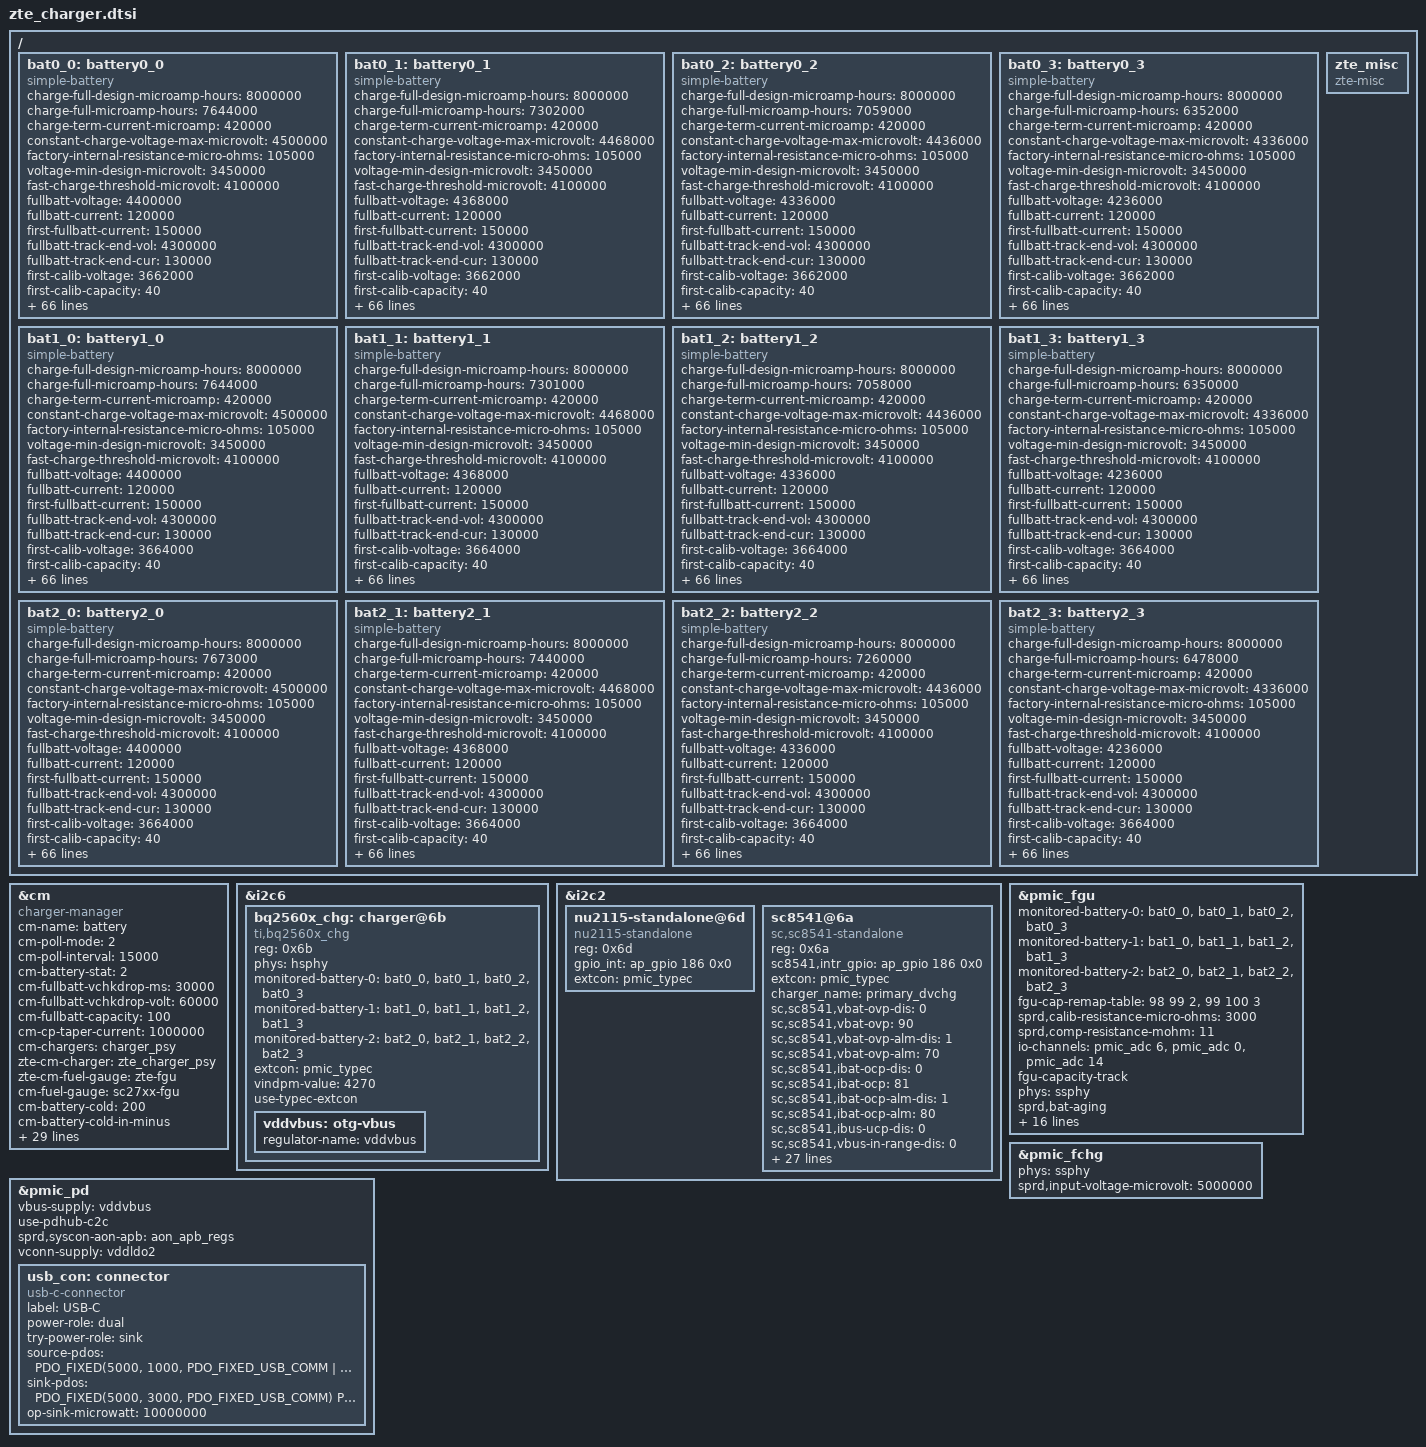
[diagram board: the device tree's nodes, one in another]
#include <dt-bindings/usb/pd.h>


/ {
	bat0_0: battery0_0 {
		compatible = "simple-battery";
		status = "okay";
		charge-full-design-microamp-hours = <5000000>;
		/*Minimum Capacity 4870*0.9 = 4383 4870*0.94 = 4558 4870*0.95 = 4626 4870*0.96 = 4675,4870*0.98 = 4772  we use *0.98 */
		charge-full-microamp-hours = <4772000>;
		charge-term-current-microamp = <420000>;
		constant-charge-voltage-max-microvolt = <4400000>;
		factory-internal-resistance-micro-ohms = <225000>;
		voltage-min-design-microvolt = <3450000>;

		fast-charge-threshold-microvolt = <4100000>;
		fullbatt-voltage = <4300000>;
		fullbatt-current = <120000>;
		first-fullbatt-current = <150000>;
		fullbatt-track-end-vol = <4295000>;
		fullbatt-track-end-cur = <130000>;
		first-calib-voltage = <3580000>;
		first-calib-capacity = <50>;

		ir-cv-offset-microvolt = <100000>;
		ir-rc-micro-ohms = <20000>;
		ir-us-upper-limit-microvolt = <4500000>;

		batt-id-list = <300 10 390 20>;  /* kohm, scud / ningde / tianmao /guanyu*/
		ocv-capacity-celsius = <20>;
		ocv-capacity-table-0 = <4374000 100>, <4308000 95>, <4250000 90>,
					<4193000 85>, <4139000 80>, <4086000 75>,
					<4037000 70>, <3992000 65>, <3951000 60>,
					<3896000 55>, <3860000 50>, <3836000 45>,
					<3814000 40>, <3797000 35>, <3784000 30>,
					<3767000 25>, <3749000 20>, <3726000 15>,
					<3697000 10>, <3683000 5>, <3400000 0>;
		/* NTC 100k, Vref 1850mV, R pull-up 110K, R pull-down 1000k */
		voltage-temp-table = <1568441 750>, <1534549 800>, <1515014 850>,
					<1475819 900>, <1402274 950>, <1334550 1000>,
					<1222195 1050>, <1131821 1100>, <1035662 1150>,
					<936426 1200>, <837104 1250>, <740441 1300>,
					<648801 1350>, <563916 1400>, <486937 1450>,
					<418193 1500>, <357806 1550>, <305304 1600>,
					<260067 1650>, <221438 1700>, <188468 1750>;
		capacity-temp-table = <25 100>, <10 100>, <0 97>, <(-10) 89>, <(-20) 57>;
		resistance-temp-table = <25 100>, <10 332>, <0 507>, <(-10) 569>, <(-20) 675>;
		charge-sdp-current-microamp = <700000 500000>;
		charge-dcp-current-microamp = <2000000 3000000>;
		charge-cdp-current-microamp = <1500000 1500000>;
		charge-unknown-current-microamp = <1000000 1000000>;
		charge-fchg-current-microamp = <3400000 2000000>;
		charge-flash-current-microamp = <3400000 2700000>;

		cap-calib-energy-density-ocv-table = <3350000 3800000>, <4150000 4350000>;
		cap-track-energy-density-ocv-table = <3400000 3722000>;

		dcp-jeita-temp-table = <1000 1030 0 4400000>,
					<1050 1080 1400000 4400000>,
					<1100 1180 1400000 4400000>,
					<1450 1420 3400000 4400000>,
					<1550 1520 2400000 4100000>;
		sdp-jeita-temp-table = <1000 1030 0 4400000>,
					<1050 1080 1400000 4400000>,
					<1100 1180 1400000 4400000>,
					<1450 1420 3400000 4400000>,
					<1550 1520 2400000 4100000>;
		cdp-jeita-temp-table = <1000 1030 0 4400000>,
					<1050 1080 1400000 4400000>,
					<1100 1180 1400000 4400000>,
					<1450 1420 3400000 4400000>,
					<1550 1520 2400000 4100000>;
		unknown-jeita-temp-table = <1000 1030 0 4400000>,
					<1050 1080 1400000 4400000>,
					<1100 1180 1400000 4400000>,
					<1450 1420 3400000 4400000>,
					<1550 1520 2400000 4100000>;
		fchg-jeita-temp-table = <1000 1030 0 4400000>,
					<1050 1080 1400000 4400000>,
					<1100 1180 1400000 4400000>,
					<1450 1420 3400000 4400000>,
					<1550 1520 2400000 4100000>;
		flash-jeita-temp-table = <1000 1030 0 4400000>,
					<1050 1080 1400000 4400000>,
					<1100 1180 1400000 4400000>,
					<1450 1420 3400000 4400000>,
					<1550 1520 2400000 4100000>;
	};

	bat0_1: battery0_1 {
		compatible = "simple-battery";
		status = "okay";
		charge-full-design-microamp-hours = <5000000>;
		/*Minimum Capacity 4870*0.9 = 4383 4870*0.94 = 4558 4870*0.95 = 4626 4870*0.96 = 4675,4870*0.98 = 4772  we use *0.98 */
		charge-full-microamp-hours = <4772000>;
		charge-term-current-microamp = <420000>;
		constant-charge-voltage-max-microvolt = <4400000>;
		factory-internal-resistance-micro-ohms = <225000>;
		voltage-min-design-microvolt = <3450000>;

		fast-charge-threshold-microvolt = <4100000>;
		fullbatt-voltage = <4300000>;
		fullbatt-current = <120000>;
		first-fullbatt-current = <150000>;
		fullbatt-track-end-vol = <4295000>;
		fullbatt-track-end-cur = <130000>;
		first-calib-voltage = <3580000>;
		first-calib-capacity = <50>;

		ir-cv-offset-microvolt = <100000>;
		ir-rc-micro-ohms = <20000>;
		ir-us-upper-limit-microvolt = <4500000>;

		batt-id-list = <300 10 390 20>;  /* kohm, scud / ningde / tianmao /guanyu*/
		ocv-capacity-celsius = <20>;
		ocv-capacity-table-0 = <4374000 100>, <4308000 95>, <4250000 90>,
					<4193000 85>, <4139000 80>, <4086000 75>,
					<4037000 70>, <3992000 65>, <3951000 60>,
					<3896000 55>, <3860000 50>, <3836000 45>,
					<3814000 40>, <3797000 35>, <3784000 30>,
					<3767000 25>, <3749000 20>, <3726000 15>,
					<3697000 10>, <3683000 5>, <3400000 0>;
		/* NTC 100k, Vref 1850mV, R pull-up 110K, R pull-down 1000k */
		voltage-temp-table = <1568441 750>, <1534549 800>, <1515014 850>,
					<1475819 900>, <1402274 950>, <1334550 1000>,
					<1222195 1050>, <1131821 1100>, <1035662 1150>,
					<936426 1200>, <837104 1250>, <740441 1300>,
					<648801 1350>, <563916 1400>, <486937 1450>,
					<418193 1500>, <357806 1550>, <305304 1600>,
					<260067 1650>, <221438 1700>, <188468 1750>;
		capacity-temp-table = <25 100>, <10 100>, <0 97>, <(-10) 89>, <(-20) 57>;
		resistance-temp-table = <25 100>, <10 332>, <0 507>, <(-10) 569>, <(-20) 675>;
		charge-sdp-current-microamp = <700000 500000>;
		charge-dcp-current-microamp = <2000000 3000000>;
		charge-cdp-current-microamp = <1500000 1500000>;
		charge-unknown-current-microamp = <1000000 1000000>;
		charge-fchg-current-microamp = <3400000 2000000>;
		charge-flash-current-microamp = <3400000 2700000>;

		cap-calib-energy-density-ocv-table = <3350000 3800000>, <4150000 4350000>;
		cap-track-energy-density-ocv-table = <3400000 3722000>;

		dcp-jeita-temp-table = <1000 1030 0 4400000>,
					<1050 1080 1400000 4400000>,
					<1100 1180 1400000 4400000>,
					<1450 1420 3400000 4400000>,
					<1550 1520 2400000 4100000>;
		sdp-jeita-temp-table = <1000 1030 0 4400000>,
					<1050 1080 1400000 4400000>,
					<1100 1180 1400000 4400000>,
					<1450 1420 3400000 4400000>,
					<1550 1520 2400000 4100000>;
		cdp-jeita-temp-table = <1000 1030 0 4400000>,
					<1050 1080 1400000 4400000>,
					<1100 1180 1400000 4400000>,
					<1450 1420 3400000 4400000>,
					<1550 1520 2400000 4100000>;
		unknown-jeita-temp-table = <1000 1030 0 4400000>,
					<1050 1080 1400000 4400000>,
					<1100 1180 1400000 4400000>,
					<1450 1420 3400000 4400000>,
					<1550 1520 2400000 4100000>;
		fchg-jeita-temp-table = <1000 1030 0 4400000>,
					<1050 1080 1400000 4400000>,
					<1100 1180 1400000 4400000>,
					<1450 1420 3400000 4400000>,
					<1550 1520 2400000 4100000>;
		flash-jeita-temp-table = <1000 1030 0 4400000>,
					<1050 1080 1400000 4400000>,
					<1100 1180 1400000 4400000>,
					<1450 1420 3400000 4400000>,
					<1550 1520 2400000 4100000>;
	};

	bat0_2: battery0_2 {
		compatible = "simple-battery";
		status = "okay";
		charge-full-design-microamp-hours = <5000000>;
		/*Minimum Capacity 4870*0.9 = 4383 4870*0.94 = 4558 4870*0.95 = 4626 4870*0.96 = 4675,4870*0.98 = 4772  we use *0.98 */
		charge-full-microamp-hours = <4772000>;
		charge-term-current-microamp = <420000>;
		constant-charge-voltage-max-microvolt = <4400000>;
		factory-internal-resistance-micro-ohms = <225000>;
		voltage-min-design-microvolt = <3450000>;

		fast-charge-threshold-microvolt = <4100000>;
		fullbatt-voltage = <4300000>;
		fullbatt-current = <120000>;
		first-fullbatt-current = <150000>;
		fullbatt-track-end-vol = <4295000>;
		fullbatt-track-end-cur = <130000>;
		first-calib-voltage = <3580000>;
		first-calib-capacity = <50>;

		ir-cv-offset-microvolt = <100000>;
		ir-rc-micro-ohms = <20000>;
		ir-us-upper-limit-microvolt = <4500000>;

		batt-id-list = <300 10 390 20>;  /* kohm, scud / ningde / tianmao /guanyu*/
		ocv-capacity-celsius = <20>;
		ocv-capacity-table-0 = <4374000 100>, <4308000 95>, <4250000 90>,
					<4193000 85>, <4139000 80>, <4086000 75>,
					<4037000 70>, <3992000 65>, <3951000 60>,
					<3896000 55>, <3860000 50>, <3836000 45>,
					<3814000 40>, <3797000 35>, <3784000 30>,
					<3767000 25>, <3749000 20>, <3726000 15>,
					<3697000 10>, <3683000 5>, <3400000 0>;
		/* NTC 100k, Vref 1850mV, R pull-up 110K, R pull-down 1000k */
		voltage-temp-table = <1568441 750>, <1534549 800>, <1515014 850>,
					<1475819 900>, <1402274 950>, <1334550 1000>,
					<1222195 1050>, <1131821 1100>, <1035662 1150>,
					<936426 1200>, <837104 1250>, <740441 1300>,
					<648801 1350>, <563916 1400>, <486937 1450>,
					<418193 1500>, <357806 1550>, <305304 1600>,
					<260067 1650>, <221438 1700>, <188468 1750>;
		capacity-temp-table = <25 100>, <10 100>, <0 97>, <(-10) 89>, <(-20) 57>;
		resistance-temp-table = <25 100>, <10 332>, <0 507>, <(-10) 569>, <(-20) 675>;
		charge-sdp-current-microamp = <700000 500000>;
		charge-dcp-current-microamp = <2000000 3000000>;
		charge-cdp-current-microamp = <1500000 1500000>;
		charge-unknown-current-microamp = <1000000 1000000>;
		charge-fchg-current-microamp = <3400000 2000000>;
		charge-flash-current-microamp = <3400000 2700000>;

		cap-calib-energy-density-ocv-table = <3350000 3800000>, <4150000 4350000>;
		cap-track-energy-density-ocv-table = <3400000 3722000>;

		dcp-jeita-temp-table = <1000 1030 0 4400000>,
					<1050 1080 1400000 4400000>,
					<1100 1180 1400000 4400000>,
					<1450 1420 3400000 4400000>,
					<1550 1520 2400000 4100000>;
		sdp-jeita-temp-table = <1000 1030 0 4400000>,
					<1050 1080 1400000 4400000>,
					<1100 1180 1400000 4400000>,
					<1450 1420 3400000 4400000>,
					<1550 1520 2400000 4100000>;
		cdp-jeita-temp-table = <1000 1030 0 4400000>,
					<1050 1080 1400000 4400000>,
					<1100 1180 1400000 4400000>,
					<1450 1420 3400000 4400000>,
					<1550 1520 2400000 4100000>;
		unknown-jeita-temp-table = <1000 1030 0 4400000>,
					<1050 1080 1400000 4400000>,
					<1100 1180 1400000 4400000>,
					<1450 1420 3400000 4400000>,
					<1550 1520 2400000 4100000>;
		fchg-jeita-temp-table = <1000 1030 0 4400000>,
					<1050 1080 1400000 4400000>,
					<1100 1180 1400000 4400000>,
					<1450 1420 3400000 4400000>,
					<1550 1520 2400000 4100000>;
		flash-jeita-temp-table = <1000 1030 0 4400000>,
					<1050 1080 1400000 4400000>,
					<1100 1180 1400000 4400000>,
					<1450 1420 3400000 4400000>,
					<1550 1520 2400000 4100000>;
	};

	bat0_3: battery0_3 {
		compatible = "simple-battery";
		status = "okay";
		charge-full-design-microamp-hours = <5000000>;
		/*Minimum Capacity 4870*0.9 = 4383 4870*0.94 = 4558 4870*0.95 = 4626 4870*0.96 = 4675,4870*0.98 = 4772  we use *0.98 */
		charge-full-microamp-hours = <4772000>;
		charge-term-current-microamp = <420000>;
		constant-charge-voltage-max-microvolt = <4400000>;
		factory-internal-resistance-micro-ohms = <225000>;
		voltage-min-design-microvolt = <3450000>;

		fast-charge-threshold-microvolt = <4100000>;
		fullbatt-voltage = <4300000>;
		fullbatt-current = <120000>;
		first-fullbatt-current = <150000>;
		fullbatt-track-end-vol = <4295000>;
		fullbatt-track-end-cur = <130000>;
		first-calib-voltage = <3580000>;
		first-calib-capacity = <50>;

		ir-cv-offset-microvolt = <100000>;
		ir-rc-micro-ohms = <20000>;
		ir-us-upper-limit-microvolt = <4500000>;

		batt-id-list = <300 10 390 20>;  /* kohm, scud / ningde / tianmao /guanyu*/
		ocv-capacity-celsius = <20>;
		ocv-capacity-table-0 = <4374000 100>, <4308000 95>, <4250000 90>,
					<4193000 85>, <4139000 80>, <4086000 75>,
					<4037000 70>, <3992000 65>, <3951000 60>,
					<3896000 55>, <3860000 50>, <3836000 45>,
					<3814000 40>, <3797000 35>, <3784000 30>,
					<3767000 25>, <3749000 20>, <3726000 15>,
					<3697000 10>, <3683000 5>, <3400000 0>;
		/* NTC 100k, Vref 1850mV, R pull-up 110K, R pull-down 1000k */
		voltage-temp-table = <1568441 750>, <1534549 800>, <1515014 850>,
					<1475819 900>, <1402274 950>, <1334550 1000>,
					<1222195 1050>, <1131821 1100>, <1035662 1150>,
					<936426 1200>, <837104 1250>, <740441 1300>,
					<648801 1350>, <563916 1400>, <486937 1450>,
					<418193 1500>, <357806 1550>, <305304 1600>,
					<260067 1650>, <221438 1700>, <188468 1750>;
		capacity-temp-table = <25 100>, <10 100>, <0 97>, <(-10) 89>, <(-20) 57>;
		resistance-temp-table = <25 100>, <10 332>, <0 507>, <(-10) 569>, <(-20) 675>;
		charge-sdp-current-microamp = <700000 500000>;
		charge-dcp-current-microamp = <2000000 3000000>;
		charge-cdp-current-microamp = <1500000 1500000>;
		charge-unknown-current-microamp = <1000000 1000000>;
		charge-fchg-current-microamp = <3400000 2000000>;
		charge-flash-current-microamp = <3400000 2700000>;

		cap-calib-energy-density-ocv-table = <3350000 3800000>, <4150000 4350000>;
		cap-track-energy-density-ocv-table = <3400000 3722000>;

		dcp-jeita-temp-table = <1000 1030 0 4400000>,
					<1050 1080 1400000 4400000>,
					<1100 1180 1400000 4400000>,
					<1450 1420 3400000 4400000>,
					<1550 1520 2400000 4100000>;
		sdp-jeita-temp-table = <1000 1030 0 4400000>,
					<1050 1080 1400000 4400000>,
					<1100 1180 1400000 4400000>,
					<1450 1420 3400000 4400000>,
					<1550 1520 2400000 4100000>;
		cdp-jeita-temp-table = <1000 1030 0 4400000>,
					<1050 1080 1400000 4400000>,
					<1100 1180 1400000 4400000>,
					<1450 1420 3400000 4400000>,
					<1550 1520 2400000 4100000>;
		unknown-jeita-temp-table = <1000 1030 0 4400000>,
					<1050 1080 1400000 4400000>,
					<1100 1180 1400000 4400000>,
					<1450 1420 3400000 4400000>,
					<1550 1520 2400000 4100000>;
		fchg-jeita-temp-table = <1000 1030 0 4400000>,
					<1050 1080 1400000 4400000>,
					<1100 1180 1400000 4400000>,
					<1450 1420 3400000 4400000>,
					<1550 1520 2400000 4100000>;
		flash-jeita-temp-table = <1000 1030 0 4400000>,
					<1050 1080 1400000 4400000>,
					<1100 1180 1400000 4400000>,
					<1450 1420 3400000 4400000>,
					<1550 1520 2400000 4100000>;
	};

	bat1_0: battery1_0 {
		compatible = "simple-battery";
		status = "okay";
		charge-full-design-microamp-hours = <5000000>;
		/*Minimum Capacity 4870*0.9 = 4383 4870*0.94 = 4558 4870*0.95 = 4626 4870*0.96 = 4675,4870*0.98 = 4772  we use *0.98 */
		charge-full-microamp-hours = <4772000>;
		charge-term-current-microamp = <420000>;
		constant-charge-voltage-max-microvolt = <4400000>;
		factory-internal-resistance-micro-ohms = <225000>;
		voltage-min-design-microvolt = <3450000>;

		fast-charge-threshold-microvolt = <4100000>;
		fullbatt-voltage = <4300000>;
		fullbatt-current = <120000>;
		first-fullbatt-current = <150000>;
		fullbatt-track-end-vol = <4295000>;
		fullbatt-track-end-cur = <130000>;
		first-calib-voltage = <3580000>;
		first-calib-capacity = <50>;

		ir-cv-offset-microvolt = <100000>;
		ir-rc-micro-ohms = <20000>;
		ir-us-upper-limit-microvolt = <4500000>;

		batt-id-list = <300 10 390 20>;  /* kohm, scud / ningde / tianmao /guanyu*/
		ocv-capacity-celsius = <20>;
		ocv-capacity-table-0 = <4374000 100>, <4308000 95>, <4250000 90>,
					<4193000 85>, <4139000 80>, <4086000 75>,
					<4037000 70>, <3992000 65>, <3951000 60>,
					<3896000 55>, <3860000 50>, <3836000 45>,
					<3814000 40>, <3797000 35>, <3784000 30>,
					<3767000 25>, <3749000 20>, <3726000 15>,
					<3697000 10>, <3683000 5>, <3400000 0>;
		/* NTC 100k, Vref 1850mV, R pull-up 110K, R pull-down 1000k */
		voltage-temp-table = <1568441 750>, <1534549 800>, <1515014 850>,
					<1475819 900>, <1402274 950>, <1334550 1000>,
					<1222195 1050>, <1131821 1100>, <1035662 1150>,
					<936426 1200>, <837104 1250>, <740441 1300>,
					<648801 1350>, <563916 1400>, <486937 1450>,
					<418193 1500>, <357806 1550>, <305304 1600>,
					<260067 1650>, <221438 1700>, <188468 1750>;
		capacity-temp-table = <25 100>, <10 100>, <0 97>, <(-10) 89>, <(-20) 57>;
		resistance-temp-table = <25 100>, <10 332>, <0 507>, <(-10) 569>, <(-20) 675>;
		charge-sdp-current-microamp = <700000 500000>;
		charge-dcp-current-microamp = <2000000 3000000>;
		charge-cdp-current-microamp = <1500000 1500000>;
		charge-unknown-current-microamp = <1000000 1000000>;
		charge-fchg-current-microamp = <3400000 2000000>;
		charge-flash-current-microamp = <3400000 2700000>;

		cap-calib-energy-density-ocv-table = <3350000 3800000>, <4150000 4350000>;
		cap-track-energy-density-ocv-table = <3400000 3722000>;

		dcp-jeita-temp-table = <1000 1030 0 4400000>,
					<1050 1080 1400000 4400000>,
					<1100 1180 1400000 4400000>,
					<1450 1420 3400000 4400000>,
					<1550 1520 2400000 4100000>;
		sdp-jeita-temp-table = <1000 1030 0 4400000>,
					<1050 1080 1400000 4400000>,
					<1100 1180 1400000 4400000>,
					<1450 1420 3400000 4400000>,
					<1550 1520 2400000 4100000>;
		cdp-jeita-temp-table = <1000 1030 0 4400000>,
					<1050 1080 1400000 4400000>,
					<1100 1180 1400000 4400000>,
					<1450 1420 3400000 4400000>,
					<1550 1520 2400000 4100000>;
		unknown-jeita-temp-table = <1000 1030 0 4400000>,
					<1050 1080 1400000 4400000>,
					<1100 1180 1400000 4400000>,
					<1450 1420 3400000 4400000>,
					<1550 1520 2400000 4100000>;
		fchg-jeita-temp-table = <1000 1030 0 4400000>,
					<1050 1080 1400000 4400000>,
					<1100 1180 1400000 4400000>,
					<1450 1420 3400000 4400000>,
					<1550 1520 2400000 4100000>;
		flash-jeita-temp-table = <1000 1030 0 4400000>,
					<1050 1080 1400000 4400000>,
					<1100 1180 1400000 4400000>,
					<1450 1420 3400000 4400000>,
					<1550 1520 2400000 4100000>;
	};

	bat1_1: battery1_1 {
		compatible = "simple-battery";
		status = "okay";
		charge-full-design-microamp-hours = <5000000>;
		/*Minimum Capacity 4870*0.9 = 4383 4870*0.94 = 4558 4870*0.95 = 4626 4870*0.96 = 4675,4870*0.98 = 4772  we use *0.98 */
		charge-full-microamp-hours = <4772000>;
		charge-term-current-microamp = <420000>;
		constant-charge-voltage-max-microvolt = <4400000>;
		factory-internal-resistance-micro-ohms = <225000>;
		voltage-min-design-microvolt = <3450000>;

		fast-charge-threshold-microvolt = <4100000>;
		fullbatt-voltage = <4300000>;
		fullbatt-current = <120000>;
		first-fullbatt-current = <150000>;
		fullbatt-track-end-vol = <4295000>;
		fullbatt-track-end-cur = <130000>;
		first-calib-voltage = <3580000>;
		first-calib-capacity = <50>;

		ir-cv-offset-microvolt = <100000>;
		ir-rc-micro-ohms = <20000>;
		ir-us-upper-limit-microvolt = <4500000>;

		batt-id-list = <300 10 390 20>;  /* kohm, scud / ningde / tianmao /guanyu*/
		ocv-capacity-celsius = <20>;
		ocv-capacity-table-0 = <4374000 100>, <4308000 95>, <4250000 90>,
					<4193000 85>, <4139000 80>, <4086000 75>,
					<4037000 70>, <3992000 65>, <3951000 60>,
					<3896000 55>, <3860000 50>, <3836000 45>,
					<3814000 40>, <3797000 35>, <3784000 30>,
					<3767000 25>, <3749000 20>, <3726000 15>,
					<3697000 10>, <3683000 5>, <3400000 0>;
		/* NTC 100k, Vref 1850mV, R pull-up 110K, R pull-down 1000k */
		voltage-temp-table = <1568441 750>, <1534549 800>, <1515014 850>,
					<1475819 900>, <1402274 950>, <1334550 1000>,
					<1222195 1050>, <1131821 1100>, <1035662 1150>,
					<936426 1200>, <837104 1250>, <740441 1300>,
					<648801 1350>, <563916 1400>, <486937 1450>,
					<418193 1500>, <357806 1550>, <305304 1600>,
					<260067 1650>, <221438 1700>, <188468 1750>;
		capacity-temp-table = <25 100>, <10 100>, <0 97>, <(-10) 89>, <(-20) 57>;
		resistance-temp-table = <25 100>, <10 332>, <0 507>, <(-10) 569>, <(-20) 675>;
		charge-sdp-current-microamp = <700000 500000>;
		charge-dcp-current-microamp = <2000000 3000000>;
		charge-cdp-current-microamp = <1500000 1500000>;
		charge-unknown-current-microamp = <1000000 1000000>;
		charge-fchg-current-microamp = <3400000 2000000>;
		charge-flash-current-microamp = <3400000 2700000>;

		cap-calib-energy-density-ocv-table = <3350000 3800000>, <4150000 4350000>;
		cap-track-energy-density-ocv-table = <3400000 3722000>;

		dcp-jeita-temp-table = <1000 1030 0 4400000>,
					<1050 1080 1400000 4400000>,
					<1100 1180 1400000 4400000>,
					<1450 1420 3400000 4400000>,
					<1550 1520 2400000 4100000>;
		sdp-jeita-temp-table = <1000 1030 0 4400000>,
					<1050 1080 1400000 4400000>,
					<1100 1180 1400000 4400000>,
					<1450 1420 3400000 4400000>,
					<1550 1520 2400000 4100000>;
		cdp-jeita-temp-table = <1000 1030 0 4400000>,
					<1050 1080 1400000 4400000>,
					<1100 1180 1400000 4400000>,
					<1450 1420 3400000 4400000>,
					<1550 1520 2400000 4100000>;
		unknown-jeita-temp-table = <1000 1030 0 4400000>,
					<1050 1080 1400000 4400000>,
					<1100 1180 1400000 4400000>,
					<1450 1420 3400000 4400000>,
					<1550 1520 2400000 4100000>;
		fchg-jeita-temp-table = <1000 1030 0 4400000>,
					<1050 1080 1400000 4400000>,
					<1100 1180 1400000 4400000>,
					<1450 1420 3400000 4400000>,
					<1550 1520 2400000 4100000>;
		flash-jeita-temp-table = <1000 1030 0 4400000>,
					<1050 1080 1400000 4400000>,
					<1100 1180 1400000 4400000>,
					<1450 1420 3400000 4400000>,
					<1550 1520 2400000 4100000>;
	};

	bat1_2: battery1_2 {
		compatible = "simple-battery";
		status = "okay";
		charge-full-design-microamp-hours = <5000000>;
		/*Minimum Capacity 4870*0.9 = 4383 4870*0.94 = 4558 4870*0.95 = 4626 4870*0.96 = 4675,4870*0.98 = 4772  we use *0.98 */
		charge-full-microamp-hours = <4772000>;
		charge-term-current-microamp = <420000>;
		constant-charge-voltage-max-microvolt = <4400000>;
		factory-internal-resistance-micro-ohms = <225000>;
		voltage-min-design-microvolt = <3450000>;

		fast-charge-threshold-microvolt = <4100000>;
		fullbatt-voltage = <4300000>;
		fullbatt-current = <120000>;
		first-fullbatt-current = <150000>;
		fullbatt-track-end-vol = <4295000>;
		fullbatt-track-end-cur = <130000>;
		first-calib-voltage = <3580000>;
		first-calib-capacity = <50>;

		ir-cv-offset-microvolt = <100000>;
		ir-rc-micro-ohms = <20000>;
		ir-us-upper-limit-microvolt = <4500000>;

		batt-id-list = <300 10 390 20>;  /* kohm, scud / ningde / tianmao /guanyu*/
		ocv-capacity-celsius = <20>;
		ocv-capacity-table-0 = <4374000 100>, <4308000 95>, <4250000 90>,
					<4193000 85>, <4139000 80>, <4086000 75>,
					<4037000 70>, <3992000 65>, <3951000 60>,
					<3896000 55>, <3860000 50>, <3836000 45>,
					<3814000 40>, <3797000 35>, <3784000 30>,
					<3767000 25>, <3749000 20>, <3726000 15>,
					<3697000 10>, <3683000 5>, <3400000 0>;
		/* NTC 100k, Vref 1850mV, R pull-up 110K, R pull-down 1000k */
		voltage-temp-table = <1568441 750>, <1534549 800>, <1515014 850>,
					<1475819 900>, <1402274 950>, <1334550 1000>,
					<1222195 1050>, <1131821 1100>, <1035662 1150>,
					<936426 1200>, <837104 1250>, <740441 1300>,
					<648801 1350>, <563916 1400>, <486937 1450>,
					<418193 1500>, <357806 1550>, <305304 1600>,
					<260067 1650>, <221438 1700>, <188468 1750>;
		capacity-temp-table = <25 100>, <10 100>, <0 97>, <(-10) 89>, <(-20) 57>;
		resistance-temp-table = <25 100>, <10 332>, <0 507>, <(-10) 569>, <(-20) 675>;
		charge-sdp-current-microamp = <700000 500000>;
		charge-dcp-current-microamp = <2000000 3000000>;
		charge-cdp-current-microamp = <1500000 1500000>;
		charge-unknown-current-microamp = <1000000 1000000>;
		charge-fchg-current-microamp = <3400000 2000000>;
		charge-flash-current-microamp = <3400000 2700000>;

		cap-calib-energy-density-ocv-table = <3350000 3800000>, <4150000 4350000>;
		cap-track-energy-density-ocv-table = <3400000 3722000>;

		dcp-jeita-temp-table = <1000 1030 0 4400000>,
					<1050 1080 1400000 4400000>,
					<1100 1180 1400000 4400000>,
					<1450 1420 3400000 4400000>,
					<1550 1520 2400000 4100000>;
		sdp-jeita-temp-table = <1000 1030 0 4400000>,
					<1050 1080 1400000 4400000>,
					<1100 1180 1400000 4400000>,
					<1450 1420 3400000 4400000>,
					<1550 1520 2400000 4100000>;
		cdp-jeita-temp-table = <1000 1030 0 4400000>,
					<1050 1080 1400000 4400000>,
					<1100 1180 1400000 4400000>,
					<1450 1420 3400000 4400000>,
					<1550 1520 2400000 4100000>;
		unknown-jeita-temp-table = <1000 1030 0 4400000>,
					<1050 1080 1400000 4400000>,
					<1100 1180 1400000 4400000>,
					<1450 1420 3400000 4400000>,
					<1550 1520 2400000 4100000>;
		fchg-jeita-temp-table = <1000 1030 0 4400000>,
					<1050 1080 1400000 4400000>,
					<1100 1180 1400000 4400000>,
					<1450 1420 3400000 4400000>,
					<1550 1520 2400000 4100000>;
		flash-jeita-temp-table = <1000 1030 0 4400000>,
					<1050 1080 1400000 4400000>,
					<1100 1180 1400000 4400000>,
					<1450 1420 3400000 4400000>,
					<1550 1520 2400000 4100000>;
	};

	bat1_3: battery1_3 {
		compatible = "simple-battery";
		status = "okay";
		charge-full-design-microamp-hours = <5000000>;
		/*Minimum Capacity 4870*0.9 = 4383 4870*0.94 = 4558 4870*0.95 = 4626 4870*0.96 = 4675,4870*0.98 = 4772  we use *0.98 */
		charge-full-microamp-hours = <4772000>;
		charge-term-current-microamp = <420000>;
		constant-charge-voltage-max-microvolt = <4400000>;
		factory-internal-resistance-micro-ohms = <225000>;
		voltage-min-design-microvolt = <3450000>;

		fast-charge-threshold-microvolt = <4100000>;
		fullbatt-voltage = <4300000>;
		fullbatt-current = <120000>;
		first-fullbatt-current = <150000>;
		fullbatt-track-end-vol = <4295000>;
		fullbatt-track-end-cur = <130000>;
		first-calib-voltage = <3580000>;
		first-calib-capacity = <50>;

		ir-cv-offset-microvolt = <100000>;
		ir-rc-micro-ohms = <20000>;
		ir-us-upper-limit-microvolt = <4500000>;

		batt-id-list = <300 10 390 20>;  /* kohm, scud / ningde / tianmao /guanyu*/
		ocv-capacity-celsius = <20>;
		ocv-capacity-table-0 = <4374000 100>, <4308000 95>, <4250000 90>,
					<4193000 85>, <4139000 80>, <4086000 75>,
					<4037000 70>, <3992000 65>, <3951000 60>,
					<3896000 55>, <3860000 50>, <3836000 45>,
					<3814000 40>, <3797000 35>, <3784000 30>,
					<3767000 25>, <3749000 20>, <3726000 15>,
					<3697000 10>, <3683000 5>, <3400000 0>;
		/* NTC 100k, Vref 1850mV, R pull-up 110K, R pull-down 1000k */
		voltage-temp-table = <1568441 750>, <1534549 800>, <1515014 850>,
					<1475819 900>, <1402274 950>, <1334550 1000>,
					<1222195 1050>, <1131821 1100>, <1035662 1150>,
					<936426 1200>, <837104 1250>, <740441 1300>,
					<648801 1350>, <563916 1400>, <486937 1450>,
					<418193 1500>, <357806 1550>, <305304 1600>,
					<260067 1650>, <221438 1700>, <188468 1750>;
		capacity-temp-table = <25 100>, <10 100>, <0 97>, <(-10) 89>, <(-20) 57>;
		resistance-temp-table = <25 100>, <10 332>, <0 507>, <(-10) 569>, <(-20) 675>;
		charge-sdp-current-microamp = <700000 500000>;
		charge-dcp-current-microamp = <2000000 3000000>;
		charge-cdp-current-microamp = <1500000 1500000>;
		charge-unknown-current-microamp = <1000000 1000000>;
		charge-fchg-current-microamp = <3400000 2000000>;
		charge-flash-current-microamp = <3400000 2700000>;

		cap-calib-energy-density-ocv-table = <3350000 3800000>, <4150000 4350000>;
		cap-track-energy-density-ocv-table = <3400000 3722000>;

		dcp-jeita-temp-table = <1000 1030 0 4400000>,
					<1050 1080 1400000 4400000>,
					<1100 1180 1400000 4400000>,
					<1450 1420 3400000 4400000>,
					<1550 1520 2400000 4100000>;
		sdp-jeita-temp-table = <1000 1030 0 4400000>,
					<1050 1080 1400000 4400000>,
					<1100 1180 1400000 4400000>,
					<1450 1420 3400000 4400000>,
					<1550 1520 2400000 4100000>;
		cdp-jeita-temp-table = <1000 1030 0 4400000>,
					<1050 1080 1400000 4400000>,
					<1100 1180 1400000 4400000>,
					<1450 1420 3400000 4400000>,
					<1550 1520 2400000 4100000>;
		unknown-jeita-temp-table = <1000 1030 0 4400000>,
					<1050 1080 1400000 4400000>,
					<1100 1180 1400000 4400000>,
					<1450 1420 3400000 4400000>,
					<1550 1520 2400000 4100000>;
		fchg-jeita-temp-table = <1000 1030 0 4400000>,
					<1050 1080 1400000 4400000>,
					<1100 1180 1400000 4400000>,
					<1450 1420 3400000 4400000>,
					<1550 1520 2400000 4100000>;
		flash-jeita-temp-table = <1000 1030 0 4400000>,
					<1050 1080 1400000 4400000>,
					<1100 1180 1400000 4400000>,
					<1450 1420 3400000 4400000>,
					<1550 1520 2400000 4100000>;
	};


	bat2_0: battery2_0 {
		compatible = "simple-battery";
		status = "okay";
		charge-full-design-microamp-hours = <5000000>;
		/*Minimum Capacity 4870*0.9 = 4383 4870*0.94 = 4558 4870*0.95 = 4626 4870*0.96 = 4675,4870*0.98 = 4772  we use *0.98 */
		charge-full-microamp-hours = <4772000>;
		charge-term-current-microamp = <420000>;
		constant-charge-voltage-max-microvolt = <4400000>;
		factory-internal-resistance-micro-ohms = <225000>;
		voltage-min-design-microvolt = <3450000>;

		fast-charge-threshold-microvolt = <4100000>;
		fullbatt-voltage = <4300000>;
		fullbatt-current = <120000>;
		first-fullbatt-current = <150000>;
		fullbatt-track-end-vol = <4295000>;
		fullbatt-track-end-cur = <130000>;
		first-calib-voltage = <3580000>;
		first-calib-capacity = <50>;

		ir-cv-offset-microvolt = <100000>;
		ir-rc-micro-ohms = <20000>;
		ir-us-upper-limit-microvolt = <4500000>;

		batt-id-list = <300 10 390 20>;  /* kohm, scud / ningde / tianmao /guanyu*/
		ocv-capacity-celsius = <20>;
		ocv-capacity-table-0 = <4374000 100>, <4308000 95>, <4250000 90>,
					<4193000 85>, <4139000 80>, <4086000 75>,
					<4037000 70>, <3992000 65>, <3951000 60>,
					<3896000 55>, <3860000 50>, <3836000 45>,
					<3814000 40>, <3797000 35>, <3784000 30>,
					<3767000 25>, <3749000 20>, <3726000 15>,
					<3697000 10>, <3683000 5>, <3400000 0>;
		/* NTC 100k, Vref 1850mV, R pull-up 110K, R pull-down 1000k */
		voltage-temp-table = <1568441 750>, <1534549 800>, <1515014 850>,
					<1475819 900>, <1402274 950>, <1334550 1000>,
					<1222195 1050>, <1131821 1100>, <1035662 1150>,
					<936426 1200>, <837104 1250>, <740441 1300>,
					<648801 1350>, <563916 1400>, <486937 1450>,
					<418193 1500>, <357806 1550>, <305304 1600>,
					<260067 1650>, <221438 1700>, <188468 1750>;
		capacity-temp-table = <25 100>, <10 100>, <0 97>, <(-10) 89>, <(-20) 57>;
		resistance-temp-table = <25 100>, <10 332>, <0 507>, <(-10) 569>, <(-20) 675>;
		charge-sdp-current-microamp = <700000 500000>;
		charge-dcp-current-microamp = <2000000 3000000>;
		charge-cdp-current-microamp = <1500000 1500000>;
		charge-unknown-current-microamp = <1000000 1000000>;
		charge-fchg-current-microamp = <3400000 2000000>;
		charge-flash-current-microamp = <3400000 2700000>;

		cap-calib-energy-density-ocv-table = <3350000 3800000>, <4150000 4350000>;
		cap-track-energy-density-ocv-table = <3400000 3722000>;

		dcp-jeita-temp-table = <1000 1030 0 4400000>,
					<1050 1080 1400000 4400000>,
					<1100 1180 1400000 4400000>,
					<1450 1420 3400000 4400000>,
					<1550 1520 2400000 4100000>;
		sdp-jeita-temp-table = <1000 1030 0 4400000>,
					<1050 1080 1400000 4400000>,
					<1100 1180 1400000 4400000>,
					<1450 1420 3400000 4400000>,
					<1550 1520 2400000 4100000>;
		cdp-jeita-temp-table = <1000 1030 0 4400000>,
					<1050 1080 1400000 4400000>,
					<1100 1180 1400000 4400000>,
					<1450 1420 3400000 4400000>,
					<1550 1520 2400000 4100000>;
		unknown-jeita-temp-table = <1000 1030 0 4400000>,
					<1050 1080 1400000 4400000>,
					<1100 1180 1400000 4400000>,
					<1450 1420 3400000 4400000>,
					<1550 1520 2400000 4100000>;
		fchg-jeita-temp-table = <1000 1030 0 4400000>,
					<1050 1080 1400000 4400000>,
					<1100 1180 1400000 4400000>,
					<1450 1420 3400000 4400000>,
					<1550 1520 2400000 4100000>;
		flash-jeita-temp-table = <1000 1030 0 4400000>,
					<1050 1080 1400000 4400000>,
					<1100 1180 1400000 4400000>,
					<1450 1420 3400000 4400000>,
					<1550 1520 2400000 4100000>;
	};

	bat2_1: battery2_1 {
		compatible = "simple-battery";
		status = "okay";
		charge-full-design-microamp-hours = <5000000>;
		/*Minimum Capacity 4870*0.9 = 4383 4870*0.94 = 4558 4870*0.95 = 4626 4870*0.96 = 4675,4870*0.98 = 4772  we use *0.98 */
		charge-full-microamp-hours = <4772000>;
		charge-term-current-microamp = <420000>;
		constant-charge-voltage-max-microvolt = <4400000>;
		factory-internal-resistance-micro-ohms = <225000>;
		voltage-min-design-microvolt = <3450000>;

		fast-charge-threshold-microvolt = <4100000>;
		fullbatt-voltage = <4300000>;
		fullbatt-current = <120000>;
		first-fullbatt-current = <150000>;
		fullbatt-track-end-vol = <4295000>;
		fullbatt-track-end-cur = <130000>;
		first-calib-voltage = <3580000>;
		first-calib-capacity = <50>;

		ir-cv-offset-microvolt = <100000>;
		ir-rc-micro-ohms = <20000>;
		ir-us-upper-limit-microvolt = <4500000>;

		batt-id-list = <300 10 390 20>;  /* kohm, scud / ningde / tianmao /guanyu*/
		ocv-capacity-celsius = <20>;
		ocv-capacity-table-0 = <4374000 100>, <4308000 95>, <4250000 90>,
					<4193000 85>, <4139000 80>, <4086000 75>,
					<4037000 70>, <3992000 65>, <3951000 60>,
					<3896000 55>, <3860000 50>, <3836000 45>,
					<3814000 40>, <3797000 35>, <3784000 30>,
					<3767000 25>, <3749000 20>, <3726000 15>,
					<3697000 10>, <3683000 5>, <3400000 0>;
		/* NTC 100k, Vref 1850mV, R pull-up 110K, R pull-down 1000k */
		voltage-temp-table = <1568441 750>, <1534549 800>, <1515014 850>,
					<1475819 900>, <1402274 950>, <1334550 1000>,
					<1222195 1050>, <1131821 1100>, <1035662 1150>,
					<936426 1200>, <837104 1250>, <740441 1300>,
					<648801 1350>, <563916 1400>, <486937 1450>,
					<418193 1500>, <357806 1550>, <305304 1600>,
					<260067 1650>, <221438 1700>, <188468 1750>;
		capacity-temp-table = <25 100>, <10 100>, <0 97>, <(-10) 89>, <(-20) 57>;
		resistance-temp-table = <25 100>, <10 332>, <0 507>, <(-10) 569>, <(-20) 675>;
		charge-sdp-current-microamp = <700000 500000>;
		charge-dcp-current-microamp = <2000000 3000000>;
		charge-cdp-current-microamp = <1500000 1500000>;
		charge-unknown-current-microamp = <1000000 1000000>;
		charge-fchg-current-microamp = <3400000 2000000>;
		charge-flash-current-microamp = <3400000 2700000>;

		cap-calib-energy-density-ocv-table = <3350000 3800000>, <4150000 4350000>;
		cap-track-energy-density-ocv-table = <3400000 3722000>;

		dcp-jeita-temp-table = <1000 1030 0 4400000>,
					<1050 1080 1400000 4400000>,
					<1100 1180 1400000 4400000>,
					<1450 1420 3400000 4400000>,
					<1550 1520 2400000 4100000>;
		sdp-jeita-temp-table = <1000 1030 0 4400000>,
					<1050 1080 1400000 4400000>,
					<1100 1180 1400000 4400000>,
					<1450 1420 3400000 4400000>,
					<1550 1520 2400000 4100000>;
		cdp-jeita-temp-table = <1000 1030 0 4400000>,
					<1050 1080 1400000 4400000>,
					<1100 1180 1400000 4400000>,
					<1450 1420 3400000 4400000>,
					<1550 1520 2400000 4100000>;
		unknown-jeita-temp-table = <1000 1030 0 4400000>,
					<1050 1080 1400000 4400000>,
					<1100 1180 1400000 4400000>,
					<1450 1420 3400000 4400000>,
					<1550 1520 2400000 4100000>;
		fchg-jeita-temp-table = <1000 1030 0 4400000>,
					<1050 1080 1400000 4400000>,
					<1100 1180 1400000 4400000>,
					<1450 1420 3400000 4400000>,
					<1550 1520 2400000 4100000>;
		flash-jeita-temp-table = <1000 1030 0 4400000>,
					<1050 1080 1400000 4400000>,
					<1100 1180 1400000 4400000>,
					<1450 1420 3400000 4400000>,
					<1550 1520 2400000 4100000>;
	};

	bat2_2: battery2_2 {
		compatible = "simple-battery";
		status = "okay";
		charge-full-design-microamp-hours = <5000000>;
		/*Minimum Capacity 4870*0.9 = 4383 4870*0.94 = 4558 4870*0.95 = 4626 4870*0.96 = 4675,4870*0.98 = 4772  we use *0.98 */
		charge-full-microamp-hours = <4772000>;
		charge-term-current-microamp = <420000>;
		constant-charge-voltage-max-microvolt = <4400000>;
		factory-internal-resistance-micro-ohms = <225000>;
		voltage-min-design-microvolt = <3450000>;

		fast-charge-threshold-microvolt = <4100000>;
		fullbatt-voltage = <4300000>;
		fullbatt-current = <120000>;
		first-fullbatt-current = <150000>;
		fullbatt-track-end-vol = <4295000>;
		fullbatt-track-end-cur = <130000>;
		first-calib-voltage = <3580000>;
		first-calib-capacity = <50>;

		ir-cv-offset-microvolt = <100000>;
		ir-rc-micro-ohms = <20000>;
		ir-us-upper-limit-microvolt = <4500000>;

		batt-id-list = <300 10 390 20>;  /* kohm, scud / ningde / tianmao /guanyu*/
		ocv-capacity-celsius = <20>;
		ocv-capacity-table-0 = <4374000 100>, <4308000 95>, <4250000 90>,
					<4193000 85>, <4139000 80>, <4086000 75>,
					<4037000 70>, <3992000 65>, <3951000 60>,
					<3896000 55>, <3860000 50>, <3836000 45>,
					<3814000 40>, <3797000 35>, <3784000 30>,
					<3767000 25>, <3749000 20>, <3726000 15>,
					<3697000 10>, <3683000 5>, <3400000 0>;
		/* NTC 100k, Vref 1850mV, R pull-up 110K, R pull-down 1000k */
		voltage-temp-table = <1568441 750>, <1534549 800>, <1515014 850>,
					<1475819 900>, <1402274 950>, <1334550 1000>,
					<1222195 1050>, <1131821 1100>, <1035662 1150>,
					<936426 1200>, <837104 1250>, <740441 1300>,
					<648801 1350>, <563916 1400>, <486937 1450>,
					<418193 1500>, <357806 1550>, <305304 1600>,
					<260067 1650>, <221438 1700>, <188468 1750>;
		capacity-temp-table = <25 100>, <10 100>, <0 97>, <(-10) 89>, <(-20) 57>;
		resistance-temp-table = <25 100>, <10 332>, <0 507>, <(-10) 569>, <(-20) 675>;
		charge-sdp-current-microamp = <700000 500000>;
		charge-dcp-current-microamp = <2000000 3000000>;
		charge-cdp-current-microamp = <1500000 1500000>;
		charge-unknown-current-microamp = <1000000 1000000>;
		charge-fchg-current-microamp = <3400000 2000000>;
		charge-flash-current-microamp = <3400000 2700000>;

		cap-calib-energy-density-ocv-table = <3350000 3800000>, <4150000 4350000>;
		cap-track-energy-density-ocv-table = <3400000 3722000>;

		dcp-jeita-temp-table = <1000 1030 0 4400000>,
					<1050 1080 1400000 4400000>,
					<1100 1180 1400000 4400000>,
					<1450 1420 3400000 4400000>,
					<1550 1520 2400000 4100000>;
		sdp-jeita-temp-table = <1000 1030 0 4400000>,
					<1050 1080 1400000 4400000>,
					<1100 1180 1400000 4400000>,
					<1450 1420 3400000 4400000>,
					<1550 1520 2400000 4100000>;
		cdp-jeita-temp-table = <1000 1030 0 4400000>,
					<1050 1080 1400000 4400000>,
					<1100 1180 1400000 4400000>,
					<1450 1420 3400000 4400000>,
					<1550 1520 2400000 4100000>;
		unknown-jeita-temp-table = <1000 1030 0 4400000>,
					<1050 1080 1400000 4400000>,
					<1100 1180 1400000 4400000>,
					<1450 1420 3400000 4400000>,
					<1550 1520 2400000 4100000>;
		fchg-jeita-temp-table = <1000 1030 0 4400000>,
					<1050 1080 1400000 4400000>,
					<1100 1180 1400000 4400000>,
					<1450 1420 3400000 4400000>,
					<1550 1520 2400000 4100000>;
		flash-jeita-temp-table = <1000 1030 0 4400000>,
					<1050 1080 1400000 4400000>,
					<1100 1180 1400000 4400000>,
					<1450 1420 3400000 4400000>,
					<1550 1520 2400000 4100000>;
	};

	bat2_3: battery2_3 {
		compatible = "simple-battery";
		status = "okay";
		charge-full-design-microamp-hours = <5000000>;
		/*Minimum Capacity 4870*0.9 = 4383 4870*0.94 = 4558 4870*0.95 = 4626 4870*0.96 = 4675,4870*0.98 = 4772  we use *0.98 */
		charge-full-microamp-hours = <4772000>;
		charge-term-current-microamp = <420000>;
		constant-charge-voltage-max-microvolt = <4400000>;
		factory-internal-resistance-micro-ohms = <225000>;
		voltage-min-design-microvolt = <3450000>;

		fast-charge-threshold-microvolt = <4100000>;
		fullbatt-voltage = <4300000>;
		fullbatt-current = <120000>;
		first-fullbatt-current = <150000>;
		fullbatt-track-end-vol = <4295000>;
		fullbatt-track-end-cur = <130000>;
		first-calib-voltage = <3580000>;
		first-calib-capacity = <50>;

		ir-cv-offset-microvolt = <100000>;
		ir-rc-micro-ohms = <20000>;
		ir-us-upper-limit-microvolt = <4500000>;

		batt-id-list = <300 10 390 20>;  /* kohm, scud / ningde / tianmao /guanyu*/
		ocv-capacity-celsius = <20>;
		ocv-capacity-table-0 = <4374000 100>, <4308000 95>, <4250000 90>,
					<4193000 85>, <4139000 80>, <4086000 75>,
					<4037000 70>, <3992000 65>, <3951000 60>,
					<3896000 55>, <3860000 50>, <3836000 45>,
					<3814000 40>, <3797000 35>, <3784000 30>,
					<3767000 25>, <3749000 20>, <3726000 15>,
					<3697000 10>, <3683000 5>, <3400000 0>;
		/* NTC 100k, Vref 1850mV, R pull-up 110K, R pull-down 1000k */
		voltage-temp-table = <1568441 750>, <1534549 800>, <1515014 850>,
					<1475819 900>, <1402274 950>, <1334550 1000>,
					<1222195 1050>, <1131821 1100>, <1035662 1150>,
					<936426 1200>, <837104 1250>, <740441 1300>,
					<648801 1350>, <563916 1400>, <486937 1450>,
					<418193 1500>, <357806 1550>, <305304 1600>,
					<260067 1650>, <221438 1700>, <188468 1750>;
		capacity-temp-table = <25 100>, <10 100>, <0 97>, <(-10) 89>, <(-20) 57>;
		resistance-temp-table = <25 100>, <10 332>, <0 507>, <(-10) 569>, <(-20) 675>;
		charge-sdp-current-microamp = <700000 500000>;
		charge-dcp-current-microamp = <2000000 3000000>;
		charge-cdp-current-microamp = <1500000 1500000>;
		charge-unknown-current-microamp = <1000000 1000000>;
		charge-fchg-current-microamp = <3400000 2000000>;
		charge-flash-current-microamp = <3400000 2700000>;

		cap-calib-energy-density-ocv-table = <3350000 3800000>, <4150000 4350000>;
		cap-track-energy-density-ocv-table = <3400000 3722000>;

		dcp-jeita-temp-table = <1000 1030 0 4400000>,
					<1050 1080 1400000 4400000>,
					<1100 1180 1400000 4400000>,
					<1450 1420 3400000 4400000>,
					<1550 1520 2400000 4100000>;
		sdp-jeita-temp-table = <1000 1030 0 4400000>,
					<1050 1080 1400000 4400000>,
					<1100 1180 1400000 4400000>,
					<1450 1420 3400000 4400000>,
					<1550 1520 2400000 4100000>;
		cdp-jeita-temp-table = <1000 1030 0 4400000>,
					<1050 1080 1400000 4400000>,
					<1100 1180 1400000 4400000>,
					<1450 1420 3400000 4400000>,
					<1550 1520 2400000 4100000>;
		unknown-jeita-temp-table = <1000 1030 0 4400000>,
					<1050 1080 1400000 4400000>,
					<1100 1180 1400000 4400000>,
					<1450 1420 3400000 4400000>,
					<1550 1520 2400000 4100000>;
		fchg-jeita-temp-table = <1000 1030 0 4400000>,
					<1050 1080 1400000 4400000>,
					<1100 1180 1400000 4400000>,
					<1450 1420 3400000 4400000>,
					<1550 1520 2400000 4100000>;
		flash-jeita-temp-table = <1000 1030 0 4400000>,
					<1050 1080 1400000 4400000>,
					<1100 1180 1400000 4400000>,
					<1450 1420 3400000 4400000>,
					<1550 1520 2400000 4100000>;
	};
};

&bat0_0 {
	charge-term-current-microamp = <420000>;
	constant-charge-voltage-max-microvolt = <4500000>;
	constant-charge-current-max-microamp = <5300000>;
	factory-internal-resistance-micro-ohms = <105000>;
	voltage-min-design-microvolt = <3450000>;
	fast-charge-threshold-microvolt = <4100000>;
	fullbatt-voltage = <4400000>;
	fullbatt-current = <120000>;
	fullbatt-track-end-vol = <4300000>;
	fullbatt-track-end-cur = <130000>;
	first-calib-voltage = <3662000>;
	first-calib-capacity = <40>;

	ir-cv-offset-microvolt = <100000>;
	ir-rc-micro-ohms = <20000>;
	ir-us-upper-limit-microvolt = <4500000>;

	batt-id-list = <270 121 430>;  /*kohm, weike, haopeng，utility*/
	charge-full-design-microamp-hours = <8000000>;
	/*7800*0.98 = 7644 */
	charge-full-microamp-hours = <7644000>;

	ocv-capacity-celsius = <25>;
	ocv-capacity-table-0 = <4455000 100>, <4393000 95>, <4338000 90>,
				<4280000 85>, <4219000 80>, <4159000 75>,
				<4101000 70>, <4048000 65>, <3999000 60>,
				<3936000 55>, <3889000 50>, <3858000 45>,
				<3833000 40>, <3814000 35>, <3797000 30>,
				<3773000 25>, <3750000 20>, <3723000 15>,
				<3693000 10>, <3682000 5>, <3400000 0>;
	/* NTC 100k, Vref 1850mV, R pull-up 110K, R pull-down 1000k */
	voltage-temp-table = <1591473 750>, <1555286 800>, <1512176 850>,
				<1459276 900>, <1395886 950>, <1322179 1000>,
				<1238711 1050>, <1147116 1100>, <1049658 1150>,
				<949081 1200>, <848416 1250>, <750447 1300>,
				<657569 1350>, <571537 1400>, <493518 1450>,
				<423845 1500>, <362641 1550>, <309430 1600>,
				<263582 1650>, <221438 1700>, <188468 1750>;
	capacity-temp-table = <25 100>, <10 99>, <0 96>, <(-10) 92>, <(-20) 82>;
	resistance-temp-table = <25 100>, <10 155>, <0 1044>, <(-10) 1113>, <(-20) 1237>;

	charge-sdp-current-microamp = <700000 500000>;
	charge-dcp-current-microamp = <7800000 2000000>;
	charge-cdp-current-microamp = <7800000 1500000>;
	charge-unknown-current-microamp = <1000000 1000000>;
	charge-fchg-current-microamp = <7800000 4000000>;
	charge-flash-current-microamp = <7800000 4000000>;

	dcp-jeita-temp-table = <1000 1030 0 4500000>,
				<1100 1080 1500000 4500000>,
				<1150 1180 1500000 4500000>,
				<1450 1420 5400000 4500000>,
				<1550 1520 3900000 4200000>;
	sdp-jeita-temp-table = <1000 1030 0 4500000>,
				<1100 1080 1500000 4500000>,
				<1150 1180 1500000 4500000>,
				<1450 1420 5400000 4500000>,
				<1550 1520 3900000 4200000>;
	cdp-jeita-temp-table = <1000 1030 0 4500000>,
				<1100 1080 1500000 4500000>,
				<1150 1180 1500000 4500000>,
				<1450 1420 5400000 4500000>,
				<1550 1520 3900000 4200000>;
	unknown-jeita-temp-table = <1000 1030 0 4500000>,
				<1100 1080 1500000 4500000>,
				<1150 1180 1500000 4500000>,
				<1450 1420 5400000 4500000>,
				<1550 1520 3900000 4200000>;

	fchg-jeita-temp-table = <1000 1030 0 4500000>,
				<1100 1080 1500000 4500000>,
				<1150 1180 1500000 4500000>,
				<1450 1420 5400000 4500000>,
				<1550 1520 3900000 4200000>;
	flash-jeita-temp-table = <1000 1030 0 4500000>,
				<1100 1080 1500000 4500000>,
				<1150 1180 1500000 4500000>,
				<1450 1420 5400000 4500000>,
				<1550 1520 3900000 4200000>;
};

&bat0_1 {
	charge-term-current-microamp = <420000>;
	constant-charge-voltage-max-microvolt = <4468000>;
	constant-charge-current-max-microamp = <5300000>;
	factory-internal-resistance-micro-ohms = <105000>;
	voltage-min-design-microvolt = <3450000>;
	fast-charge-threshold-microvolt = <4100000>;
	fullbatt-voltage = <4368000>;
	fullbatt-current = <120000>;
	fullbatt-track-end-vol = <4300000>;
	fullbatt-track-end-cur = <130000>;
	first-calib-voltage = <3662000>;
	first-calib-capacity = <40>;

	ir-cv-offset-microvolt = <100000>;
	ir-rc-micro-ohms = <20000>;
	ir-us-upper-limit-microvolt = <4500000>;

	batt-id-list = <270 121 430>;  /*kohm, weike, haopeng，utility*/
	charge-full-design-microamp-hours = <8000000>;
	/*7800*0.98 = 7644 */
	charge-full-microamp-hours = <7302000>;

	ocv-capacity-celsius = <25>;
	ocv-capacity-table-0 = <4423000 100>, <4362000 95>, <4309000 90>,
				<4253000 85>, <4194000 80>, <4135000 75>,
				<4079000 70>, <4028000 65>, <3980000 60>,
				<3919000 55>, <3874000 50>, <3844000 45>,
				<3819000 40>, <3801000 35>, <3784000 30>,
				<3761000 25>, <3739000 20>, <3713000 15>,
				<3684000 10>, <3673000 5>, <3400000 0>;
	/* NTC 100k, Vref 1850mV, R pull-up 110K, R pull-down 1000k */
	voltage-temp-table = <1591473 750>, <1555286 800>, <1512176 850>,
				<1459276 900>, <1395886 950>, <1322179 1000>,
				<1238711 1050>, <1147116 1100>, <1049658 1150>,
				<949081 1200>, <848416 1250>, <750447 1300>,
				<657569 1350>, <571537 1400>, <493518 1450>,
				<423845 1500>, <362641 1550>, <309430 1600>,
				<263582 1650>, <221438 1700>, <188468 1750>;
	capacity-temp-table = <25 100>, <10 99>, <0 96>, <(-10) 92>, <(-20) 82>;
	resistance-temp-table = <25 100>, <10 155>, <0 1044>, <(-10) 1113>, <(-20) 1237>;

	charge-sdp-current-microamp = <700000 500000>;
	charge-dcp-current-microamp = <7800000 2000000>;
	charge-cdp-current-microamp = <7800000 1500000>;
	charge-unknown-current-microamp = <1000000 1000000>;
	charge-fchg-current-microamp = <7800000 4000000>;
	charge-flash-current-microamp = <7800000 4000000>;

	dcp-jeita-temp-table = <1000 1030 0 4500000>,
				<1100 1080 1500000 4500000>,
				<1150 1180 1500000 4500000>,
				<1450 1420 5400000 4500000>,
				<1550 1520 3900000 4200000>;
	sdp-jeita-temp-table = <1000 1030 0 4500000>,
				<1100 1080 1500000 4500000>,
				<1150 1180 1500000 4500000>,
				<1450 1420 5400000 4500000>,
				<1550 1520 3900000 4200000>;
	cdp-jeita-temp-table = <1000 1030 0 4500000>,
				<1100 1080 1500000 4500000>,
				<1150 1180 1500000 4500000>,
				<1450 1420 5400000 4500000>,
				<1550 1520 3900000 4200000>;
	unknown-jeita-temp-table = <1000 1030 0 4500000>,
				<1100 1080 1500000 4500000>,
				<1150 1180 1500000 4500000>,
				<1450 1420 5400000 4500000>,
				<1550 1520 3900000 4200000>;

	fchg-jeita-temp-table = <1000 1030 0 4500000>,
				<1100 1080 1500000 4500000>,
				<1150 1180 1500000 4500000>,
				<1450 1420 5400000 4500000>,
				<1550 1520 3900000 4200000>;
	flash-jeita-temp-table = <1000 1030 0 4500000>,
				<1100 1080 1500000 4500000>,
				<1150 1180 1500000 4500000>,
				<1450 1420 5400000 4500000>,
				<1550 1520 3900000 4200000>;
};

&bat0_2 {
	charge-term-current-microamp = <420000>;
	constant-charge-voltage-max-microvolt = <4436000>;
	constant-charge-current-max-microamp = <5300000>;
	factory-internal-resistance-micro-ohms = <105000>;
	voltage-min-design-microvolt = <3450000>;
	fast-charge-threshold-microvolt = <4100000>;
	fullbatt-voltage = <4336000>;
	fullbatt-current = <120000>;
	fullbatt-track-end-vol = <4300000>;
	fullbatt-track-end-cur = <130000>;
	first-calib-voltage = <3662000>;
	first-calib-capacity = <40>;

	ir-cv-offset-microvolt = <100000>;
	ir-rc-micro-ohms = <20000>;
	ir-us-upper-limit-microvolt = <4500000>;

	batt-id-list = <270 121 430>;  /*kohm, weike, haopeng，utility*/
	charge-full-design-microamp-hours = <8000000>;
	/*7800*0.98 = 7644 */
	charge-full-microamp-hours = <7059000>;

	ocv-capacity-celsius = <25>;
	ocv-capacity-table-0 = <4391000 100>, <4332000 95>, <4281000 90>,
				<4226000 85>, <4169000 80>, <4112000 75>,
				<4058000 70>, <4008000 65>, <3962000 60>,
				<3903000 55>, <3859000 50>, <3830000 45>,
				<3806000 40>, <3788000 35>, <3772000 30>,
				<3750000 25>, <3728000 20>, <3703000 15>,
				<3675000 10>, <3664000 5>, <3400000 0>;
	/* NTC 100k, Vref 1850mV, R pull-up 110K, R pull-down 1000k */
	voltage-temp-table = <1591473 750>, <1555286 800>, <1512176 850>,
				<1459276 900>, <1395886 950>, <1322179 1000>,
				<1238711 1050>, <1147116 1100>, <1049658 1150>,
				<949081 1200>, <848416 1250>, <750447 1300>,
				<657569 1350>, <571537 1400>, <493518 1450>,
				<423845 1500>, <362641 1550>, <309430 1600>,
				<263582 1650>, <221438 1700>, <188468 1750>;
	capacity-temp-table = <25 100>, <10 99>, <0 96>, <(-10) 92>, <(-20) 82>;
	resistance-temp-table = <25 100>, <10 155>, <0 1044>, <(-10) 1113>, <(-20) 1237>;

	charge-sdp-current-microamp = <700000 500000>;
	charge-dcp-current-microamp = <7800000 2000000>;
	charge-cdp-current-microamp = <7800000 1500000>;
	charge-unknown-current-microamp = <1000000 1000000>;
	charge-fchg-current-microamp = <7800000 4000000>;
	charge-flash-current-microamp = <7800000 4000000>;

	dcp-jeita-temp-table = <1000 1030 0 4500000>,
				<1100 1080 1500000 4500000>,
				<1150 1180 1500000 4500000>,
				<1450 1420 5400000 4500000>,
				<1550 1520 3900000 4200000>;
	sdp-jeita-temp-table = <1000 1030 0 4500000>,
				<1100 1080 1500000 4500000>,
				<1150 1180 1500000 4500000>,
				<1450 1420 5400000 4500000>,
				<1550 1520 3900000 4200000>;
	cdp-jeita-temp-table = <1000 1030 0 4500000>,
				<1100 1080 1500000 4500000>,
				<1150 1180 1500000 4500000>,
				<1450 1420 5400000 4500000>,
				<1550 1520 3900000 4200000>;
	unknown-jeita-temp-table = <1000 1030 0 4500000>,
				<1100 1080 1500000 4500000>,
				<1150 1180 1500000 4500000>,
				<1450 1420 5400000 4500000>,
				<1550 1520 3900000 4200000>;

	fchg-jeita-temp-table = <1000 1030 0 4500000>,
				<1100 1080 1500000 4500000>,
				<1150 1180 1500000 4500000>,
				<1450 1420 5400000 4500000>,
				<1550 1520 3900000 4200000>;
	flash-jeita-temp-table = <1000 1030 0 4500000>,
				<1100 1080 1500000 4500000>,
				<1150 1180 1500000 4500000>,
				<1450 1420 5400000 4500000>,
				<1550 1520 3900000 4200000>;
};

&bat0_3 {
	charge-term-current-microamp = <420000>;
	constant-charge-voltage-max-microvolt = <4336000>;
	constant-charge-current-max-microamp = <5300000>;
	factory-internal-resistance-micro-ohms = <105000>;
	voltage-min-design-microvolt = <3450000>;
	fast-charge-threshold-microvolt = <4100000>;
	fullbatt-voltage = <4236000>;
	fullbatt-current = <120000>;
	fullbatt-track-end-vol = <4300000>;
	fullbatt-track-end-cur = <130000>;
	first-calib-voltage = <3662000>;
	first-calib-capacity = <40>;

	ir-cv-offset-microvolt = <100000>;
	ir-rc-micro-ohms = <20000>;
	ir-us-upper-limit-microvolt = <4500000>;

	batt-id-list = <270 121 430>;  /*kohm, weike, haopeng，utility*/
	charge-full-design-microamp-hours = <8000000>;
	/*7800*0.98 = 7644 */
	charge-full-microamp-hours = <6352000>;

	ocv-capacity-celsius = <25>;
	ocv-capacity-table-0 = <4291000 100>, <4238000 95>, <4192000 90>,
				<4143000 85>, <4091000 80>, <4041000 75>,
				<3992000 70>, <3947000 65>, <3905000 60>,
				<3852000 55>, <3812000 50>, <3786000 45>,
				<3765000 40>, <3749000 35>, <3735000 30>,
				<3715000 25>, <3695000 20>, <3672000 15>,
				<3647000 10>, <3638000 5>, <3400000 0>;
	/* NTC 100k, Vref 1850mV, R pull-up 110K, R pull-down 1000k */
	voltage-temp-table = <1591473 750>, <1555286 800>, <1512176 850>,
				<1459276 900>, <1395886 950>, <1322179 1000>,
				<1238711 1050>, <1147116 1100>, <1049658 1150>,
				<949081 1200>, <848416 1250>, <750447 1300>,
				<657569 1350>, <571537 1400>, <493518 1450>,
				<423845 1500>, <362641 1550>, <309430 1600>,
				<263582 1650>, <221438 1700>, <188468 1750>;
	capacity-temp-table = <25 100>, <10 99>, <0 96>, <(-10) 92>, <(-20) 82>;
	resistance-temp-table = <25 100>, <10 155>, <0 1044>, <(-10) 1113>, <(-20) 1237>;

	charge-sdp-current-microamp = <700000 500000>;
	charge-dcp-current-microamp = <7800000 2000000>;
	charge-cdp-current-microamp = <7800000 1500000>;
	charge-unknown-current-microamp = <1000000 1000000>;
	charge-fchg-current-microamp = <7800000 4000000>;
	charge-flash-current-microamp = <7800000 4000000>;

	dcp-jeita-temp-table = <1000 1030 0 4500000>,
				<1100 1080 1500000 4500000>,
				<1150 1180 1500000 4500000>,
				<1450 1420 5400000 4500000>,
				<1550 1520 3900000 4200000>;
	sdp-jeita-temp-table = <1000 1030 0 4500000>,
				<1100 1080 1500000 4500000>,
				<1150 1180 1500000 4500000>,
				<1450 1420 5400000 4500000>,
				<1550 1520 3900000 4200000>;
	cdp-jeita-temp-table = <1000 1030 0 4500000>,
				<1100 1080 1500000 4500000>,
				<1150 1180 1500000 4500000>,
				<1450 1420 5400000 4500000>,
				<1550 1520 3900000 4200000>;
	unknown-jeita-temp-table = <1000 1030 0 4500000>,
				<1100 1080 1500000 4500000>,
				<1150 1180 1500000 4500000>,
				<1450 1420 5400000 4500000>,
				<1550 1520 3900000 4200000>;

	fchg-jeita-temp-table = <1000 1030 0 4500000>,
				<1100 1080 1500000 4500000>,
				<1150 1180 1500000 4500000>,
				<1450 1420 5400000 4500000>,
				<1550 1520 3900000 4200000>;
	flash-jeita-temp-table = <1000 1030 0 4500000>,
				<1100 1080 1500000 4500000>,
				<1150 1180 1500000 4500000>,
				<1450 1420 5400000 4500000>,
				<1550 1520 3900000 4200000>;
};

&bat1_0 {
	charge-term-current-microamp = <420000>;
	constant-charge-voltage-max-microvolt = <4500000>;
	constant-charge-current-max-microamp = <8000000>;
	factory-internal-resistance-micro-ohms = <105000>;
	voltage-min-design-microvolt = <3450000>;
	fast-charge-threshold-microvolt = <4100000>;
	fullbatt-voltage = <4400000>;
	fullbatt-current = <120000>;
	fullbatt-track-end-vol = <4300000>;
	fullbatt-track-end-cur = <130000>;
	first-calib-voltage = <3664000>;
	first-calib-capacity = <40>;

	ir-cv-offset-microvolt = <100000>;
	ir-rc-micro-ohms = <20000>;
	ir-us-upper-limit-microvolt = <4500000>;

	ocv-capacity-celsius = <25>;
	batt-id-list = <270 121 430>;  /*kohm, weike, haopeng，utility*/
	charge-full-design-microamp-hours = <8000000>;
	/*7800*0.98 = 7644 */
	charge-full-microamp-hours = <7644000>;

	ocv-capacity-table-0 = <4453000 100>, <4393000 95>, <4341000 90>,
				<4284000 85>, <4223000 80>, <4162000 75>,
				<4103000 70>, <4050000 65>, <4001000 60>,
				<3945000 55>, <3890000 50>, <3858000 45>,
				<3833000 40>, <3814000 35>, <3797000 30>,
				<3775000 25>, <3752000 20>, <3727000 15>,
				<3693000 10>, <3684000 5>, <3400000 0>;
	/* NTC 100k, Vref 1850mV, R pull-up 110K, R pull-down 1000k */
	voltage-temp-table = <1591473 750>, <1555286 800>, <1512176 850>,
				<1459276 900>, <1395886 950>, <1322179 1000>,
				<1238711 1050>, <1147116 1100>, <1049658 1150>,
				<949081 1200>, <848416 1250>, <750447 1300>,
				<657569 1350>, <571537 1400>, <493518 1450>,
				<423845 1500>, <362641 1550>, <309430 1600>,
				<263582 1650>, <221438 1700>, <188468 1750>;
	capacity-temp-table = <25 100>, <10 100>, <0 93>, <(-10) 87>, <(-20) 76>;
	resistance-temp-table = <25 100>, <10 176>, <0 1074>, <(-10) 1171>, <(-20) 1287>;

	charge-sdp-current-microamp = <700000 500000>;
	charge-dcp-current-microamp = <7800000 2000000>;
	charge-cdp-current-microamp = <7800000 1500000>;
	charge-unknown-current-microamp = <1000000 1000000>;
	charge-fchg-current-microamp = <7800000 4000000>;
	charge-flash-current-microamp = <7800000 4000000>;

	dcp-jeita-temp-table = <1000 1030 0 4500000>,
				<1100 1080 1500000 4500000>,
				<1150 1180 1500000 4500000>,
				<1450 1420 5400000 4500000>,
				<1550 1520 3900000 4200000>;
	sdp-jeita-temp-table = <1000 1030 0 4500000>,
				<1100 1080 1500000 4500000>,
				<1150 1180 1500000 4500000>,
				<1450 1420 5400000 4500000>,
				<1550 1520 3900000 4200000>;
	cdp-jeita-temp-table = <1000 1030 0 4500000>,
				<1100 1080 1500000 4500000>,
				<1150 1180 1500000 4500000>,
				<1450 1420 5400000 4500000>,
				<1550 1520 3900000 4200000>;
	unknown-jeita-temp-table = <1000 1030 0 4500000>,
				<1100 1080 1500000 4500000>,
				<1150 1180 1500000 4500000>,
				<1450 1420 5400000 4500000>,
				<1550 1520 3900000 4200000>;

	fchg-jeita-temp-table = <1000 1030 0 4500000>,
				<1100 1080 1500000 4500000>,
				<1150 1180 1500000 4500000>,
				<1450 1420 5400000 4500000>,
				<1550 1520 3900000 4200000>;
	flash-jeita-temp-table = <1000 1030 0 4500000>,
				<1100 1080 1500000 4500000>,
				<1150 1180 1500000 4500000>,
				<1450 1420 5400000 4500000>,
				<1550 1520 3900000 4200000>;
};

&bat1_1 {
	charge-term-current-microamp = <420000>;
	constant-charge-voltage-max-microvolt = <4468000>;
	constant-charge-current-max-microamp = <8000000>;
	factory-internal-resistance-micro-ohms = <105000>;
	voltage-min-design-microvolt = <3450000>;
	fast-charge-threshold-microvolt = <4100000>;
	fullbatt-voltage = <4368000>;
	fullbatt-current = <120000>;
	fullbatt-track-end-vol = <4300000>;
	fullbatt-track-end-cur = <130000>;
	first-calib-voltage = <3664000>;
	first-calib-capacity = <40>;

	ir-cv-offset-microvolt = <100000>;
	ir-rc-micro-ohms = <20000>;
	ir-us-upper-limit-microvolt = <4500000>;

	ocv-capacity-celsius = <25>;
	batt-id-list = <270 121 430>;  /*kohm, weike, haopeng，utility*/
	charge-full-design-microamp-hours = <8000000>;
	/*7800*0.98 = 7644 */
	charge-full-microamp-hours = <7301000>;

	ocv-capacity-table-0 = <4421000 100>, <4362000 95>, <4312000 90>,
				<4257000 85>, <4197000 80>, <4138000 75>,
				<4081000 70>, <4030000 65>, <3982000 60>,
				<3928000 55>, <3875000 50>, <3844000 45>,
				<3819000 40>, <3801000 35>, <3784000 30>,
				<3763000 25>, <3741000 20>, <3717000 15>,
				<3684000 10>, <3675000 5>, <3400000 0>;
	/* NTC 100k, Vref 1850mV, R pull-up 110K, R pull-down 1000k */
	voltage-temp-table = <1591473 750>, <1555286 800>, <1512176 850>,
				<1459276 900>, <1395886 950>, <1322179 1000>,
				<1238711 1050>, <1147116 1100>, <1049658 1150>,
				<949081 1200>, <848416 1250>, <750447 1300>,
				<657569 1350>, <571537 1400>, <493518 1450>,
				<423845 1500>, <362641 1550>, <309430 1600>,
				<263582 1650>, <221438 1700>, <188468 1750>;
	capacity-temp-table = <25 100>, <10 100>, <0 93>, <(-10) 87>, <(-20) 76>;
	resistance-temp-table = <25 100>, <10 176>, <0 1074>, <(-10) 1171>, <(-20) 1287>;

	charge-sdp-current-microamp = <700000 500000>;
	charge-dcp-current-microamp = <7800000 2000000>;
	charge-cdp-current-microamp = <7800000 1500000>;
	charge-unknown-current-microamp = <1000000 1000000>;
	charge-fchg-current-microamp = <7800000 4000000>;
	charge-flash-current-microamp = <7800000 4000000>;

	dcp-jeita-temp-table = <1000 1030 0 4500000>,
				<1100 1080 1500000 4500000>,
				<1150 1180 1500000 4500000>,
				<1450 1420 5400000 4500000>,
				<1550 1520 3900000 4200000>;
	sdp-jeita-temp-table = <1000 1030 0 4500000>,
				<1100 1080 1500000 4500000>,
				<1150 1180 1500000 4500000>,
				<1450 1420 5400000 4500000>,
				<1550 1520 3900000 4200000>;
	cdp-jeita-temp-table = <1000 1030 0 4500000>,
				<1100 1080 1500000 4500000>,
				<1150 1180 1500000 4500000>,
				<1450 1420 5400000 4500000>,
				<1550 1520 3900000 4200000>;
	unknown-jeita-temp-table = <1000 1030 0 4500000>,
				<1100 1080 1500000 4500000>,
				<1150 1180 1500000 4500000>,
				<1450 1420 5400000 4500000>,
				<1550 1520 3900000 4200000>;

	fchg-jeita-temp-table = <1000 1030 0 4500000>,
				<1100 1080 1500000 4500000>,
				<1150 1180 1500000 4500000>,
				<1450 1420 5400000 4500000>,
				<1550 1520 3900000 4200000>;
	flash-jeita-temp-table = <1000 1030 0 4500000>,
				<1100 1080 1500000 4500000>,
				<1150 1180 1500000 4500000>,
				<1450 1420 5400000 4500000>,
				<1550 1520 3900000 4200000>;
};

&bat1_2 {
	charge-term-current-microamp = <420000>;
	constant-charge-voltage-max-microvolt = <4436000>;
	constant-charge-current-max-microamp = <8000000>;
	factory-internal-resistance-micro-ohms = <105000>;
	voltage-min-design-microvolt = <3450000>;
	fast-charge-threshold-microvolt = <4100000>;
	fullbatt-voltage = <4336000>;
	fullbatt-current = <120000>;
	fullbatt-track-end-vol = <4300000>;
	fullbatt-track-end-cur = <130000>;
	first-calib-voltage = <3664000>;
	first-calib-capacity = <40>;

	ir-cv-offset-microvolt = <100000>;
	ir-rc-micro-ohms = <20000>;
	ir-us-upper-limit-microvolt = <4500000>;

	ocv-capacity-celsius = <25>;
	batt-id-list = <270 121 430>;  /*kohm, weike, haopeng，utility*/
	charge-full-design-microamp-hours = <8000000>;
	/*7800*0.98 = 7644 */
	charge-full-microamp-hours = <7058000>;

	ocv-capacity-table-0 = <4389000 100>, <4332000 95>, <4283000 90>,
				<4230000 85>, <4172000 80>, <4115000 75>,
				<4060000 70>, <4010000 65>, <3964000 60>,
				<3911000 55>, <3860000 50>, <3830000 45>,
				<3806000 40>, <3788000 35>, <3772000 30>,
				<3752000 25>, <3730000 20>, <3707000 15>,
				<3675000 10>, <3666000 5>, <3400000 0>;
	/* NTC 100k, Vref 1850mV, R pull-up 110K, R pull-down 1000k */
	voltage-temp-table = <1591473 750>, <1555286 800>, <1512176 850>,
				<1459276 900>, <1395886 950>, <1322179 1000>,
				<1238711 1050>, <1147116 1100>, <1049658 1150>,
				<949081 1200>, <848416 1250>, <750447 1300>,
				<657569 1350>, <571537 1400>, <493518 1450>,
				<423845 1500>, <362641 1550>, <309430 1600>,
				<263582 1650>, <221438 1700>, <188468 1750>;
	capacity-temp-table = <25 100>, <10 100>, <0 93>, <(-10) 87>, <(-20) 76>;
	resistance-temp-table = <25 100>, <10 176>, <0 1074>, <(-10) 1171>, <(-20) 1287>;

	charge-sdp-current-microamp = <700000 500000>;
	charge-dcp-current-microamp = <7800000 2000000>;
	charge-cdp-current-microamp = <7800000 1500000>;
	charge-unknown-current-microamp = <1000000 1000000>;
	charge-fchg-current-microamp = <7800000 4000000>;
	charge-flash-current-microamp = <7800000 4000000>;

	dcp-jeita-temp-table = <1000 1030 0 4500000>,
				<1100 1080 1500000 4500000>,
				<1150 1180 1500000 4500000>,
				<1450 1420 5400000 4500000>,
				<1550 1520 3900000 4200000>;
	sdp-jeita-temp-table = <1000 1030 0 4500000>,
				<1100 1080 1500000 4500000>,
				<1150 1180 1500000 4500000>,
				<1450 1420 5400000 4500000>,
				<1550 1520 3900000 4200000>;
	cdp-jeita-temp-table = <1000 1030 0 4500000>,
				<1100 1080 1500000 4500000>,
				<1150 1180 1500000 4500000>,
				<1450 1420 5400000 4500000>,
				<1550 1520 3900000 4200000>;
	unknown-jeita-temp-table = <1000 1030 0 4500000>,
				<1100 1080 1500000 4500000>,
				<1150 1180 1500000 4500000>,
				<1450 1420 5400000 4500000>,
				<1550 1520 3900000 4200000>;

	fchg-jeita-temp-table = <1000 1030 0 4500000>,
				<1100 1080 1500000 4500000>,
				<1150 1180 1500000 4500000>,
				<1450 1420 5400000 4500000>,
				<1550 1520 3900000 4200000>;
	flash-jeita-temp-table = <1000 1030 0 4500000>,
				<1100 1080 1500000 4500000>,
				<1150 1180 1500000 4500000>,
				<1450 1420 5400000 4500000>,
				<1550 1520 3900000 4200000>;
};

&bat1_3 {
	charge-term-current-microamp = <420000>;
	constant-charge-voltage-max-microvolt = <4336000>;
	constant-charge-current-max-microamp = <8000000>;
	factory-internal-resistance-micro-ohms = <105000>;
	voltage-min-design-microvolt = <3450000>;
	fast-charge-threshold-microvolt = <4100000>;
	fullbatt-voltage = <4236000>;
	fullbatt-current = <120000>;
	fullbatt-track-end-vol = <4300000>;
	fullbatt-track-end-cur = <130000>;
	first-calib-voltage = <3664000>;
	first-calib-capacity = <40>;

	ir-cv-offset-microvolt = <100000>;
	ir-rc-micro-ohms = <20000>;
	ir-us-upper-limit-microvolt = <4500000>;

	ocv-capacity-celsius = <25>;
	batt-id-list = <270 121 430>;  /*kohm, weike, haopeng，utility*/
	charge-full-design-microamp-hours = <8000000>;
	/*7800*0.98 = 7644 */
	charge-full-microamp-hours = <6350000>;

	ocv-capacity-table-0 = <4289000 100>, <4238000 95>, <4194000 90>,
				<4146000 85>, <4094000 80>, <4043000 75>,
				<3993000 70>, <3948000 65>, <3907000 60>,
				<3860000 55>, <3813000 50>, <3786000 45>,
				<3765000 40>, <3749000 35>, <3735000 30>,
				<3716000 25>, <3697000 20>, <3676000 15>,
				<3647000 10>, <3639000 5>, <3400000 0>;
	/* NTC 100k, Vref 1850mV, R pull-up 110K, R pull-down 1000k */
	voltage-temp-table = <1591473 750>, <1555286 800>, <1512176 850>,
				<1459276 900>, <1395886 950>, <1322179 1000>,
				<1238711 1050>, <1147116 1100>, <1049658 1150>,
				<949081 1200>, <848416 1250>, <750447 1300>,
				<657569 1350>, <571537 1400>, <493518 1450>,
				<423845 1500>, <362641 1550>, <309430 1600>,
				<263582 1650>, <221438 1700>, <188468 1750>;
	capacity-temp-table = <25 100>, <10 100>, <0 93>, <(-10) 87>, <(-20) 76>;
	resistance-temp-table = <25 100>, <10 176>, <0 1074>, <(-10) 1171>, <(-20) 1287>;

	charge-sdp-current-microamp = <700000 500000>;
	charge-dcp-current-microamp = <7800000 2000000>;
	charge-cdp-current-microamp = <7800000 1500000>;
	charge-unknown-current-microamp = <1000000 1000000>;
	charge-fchg-current-microamp = <7800000 4000000>;
	charge-flash-current-microamp = <7800000 4000000>;

	dcp-jeita-temp-table = <1000 1030 0 4500000>,
				<1100 1080 1500000 4500000>,
				<1150 1180 1500000 4500000>,
				<1450 1420 5400000 4500000>,
				<1550 1520 3900000 4200000>;
	sdp-jeita-temp-table = <1000 1030 0 4500000>,
				<1100 1080 1500000 4500000>,
				<1150 1180 1500000 4500000>,
				<1450 1420 5400000 4500000>,
				<1550 1520 3900000 4200000>;
	cdp-jeita-temp-table = <1000 1030 0 4500000>,
				<1100 1080 1500000 4500000>,
				<1150 1180 1500000 4500000>,
				<1450 1420 5400000 4500000>,
				<1550 1520 3900000 4200000>;
	unknown-jeita-temp-table = <1000 1030 0 4500000>,
				<1100 1080 1500000 4500000>,
				<1150 1180 1500000 4500000>,
				<1450 1420 5400000 4500000>,
				<1550 1520 3900000 4200000>;

	fchg-jeita-temp-table = <1000 1030 0 4500000>,
				<1100 1080 1500000 4500000>,
				<1150 1180 1500000 4500000>,
				<1450 1420 5400000 4500000>,
				<1550 1520 3900000 4200000>;
	flash-jeita-temp-table = <1000 1030 0 4500000>,
				<1100 1080 1500000 4500000>,
				<1150 1180 1500000 4500000>,
				<1450 1420 5400000 4500000>,
				<1550 1520 3900000 4200000>;
};


&bat2_0 {
	charge-term-current-microamp = <420000>;
	constant-charge-voltage-max-microvolt = <4500000>;
	constant-charge-current-max-microamp = <8000000>;
	factory-internal-resistance-micro-ohms = <105000>;
	voltage-min-design-microvolt = <3450000>;
	fast-charge-threshold-microvolt = <4100000>;
	fullbatt-voltage = <4400000>;
	fullbatt-current = <120000>;
	fullbatt-track-end-vol = <4300000>;
	fullbatt-track-end-cur = <130000>;
	first-calib-voltage = <3664000>;
	first-calib-capacity = <40>;

	ir-cv-offset-microvolt = <100000>;
	ir-rc-micro-ohms = <20000>;
	ir-us-upper-limit-microvolt = <4500000>;

	ocv-capacity-celsius = <25>;
	batt-id-list = <270 121 430>;  /*kohm, weike, haopeng，utility*/
	charge-full-design-microamp-hours = <8000000>;
	/*7830*0.98 = 7673 */
	charge-full-microamp-hours = <7673000>;

	ocv-capacity-table-0 = <4454000 100>, <4399000 95>, <4347000 90>,
				<4291000 85>, <4230000 80>, <4169000 75>,
				<4111000 70>, <4056000 65>, <4005000 60>,
				<3946000 55>, <3898000 50>, <3865000 45>,
				<3839000 40>, <3817000 35>, <3797000 30>,
				<3765000 25>, <3740000 20>, <3713000 15>,
				<3682000 10>, <3671000 5>, <3400000 0>;
	/* NTC 100k, Vref 1850mV, R pull-up 110K, R pull-down 1000k */
	voltage-temp-table = <1591473 750>, <1555286 800>, <1512176 850>,
				<1459276 900>, <1395886 950>, <1322179 1000>,
				<1238711 1050>, <1147116 1100>, <1049658 1150>,
				<949081 1200>, <848416 1250>, <750447 1300>,
				<657569 1350>, <571537 1400>, <493518 1450>,
				<423845 1500>, <362641 1550>, <309430 1600>,
				<263582 1650>, <221438 1700>, <188468 1750>;
	capacity-temp-table = <25 100>, <10 99>, <0 96>, <(-10) 91>, <(-20) 85>;
	resistance-temp-table = <25 100>, <10 135>, <0 1074>, <(-10) 1117>, <(-20) 1206>;

	charge-sdp-current-microamp = <700000 500000>;
	charge-dcp-current-microamp = <7800000 2000000>;
	charge-cdp-current-microamp = <7800000 1500000>;
	charge-unknown-current-microamp = <1000000 1000000>;
	charge-fchg-current-microamp = <7800000 4000000>;
	charge-flash-current-microamp = <7800000 4000000>;

	dcp-jeita-temp-table = <1000 1030 0 4500000>,
				<1100 1080 1500000 4500000>,
				<1150 1180 1500000 4500000>,
				<1450 1420 5400000 4500000>,
				<1550 1520 3900000 4200000>;
	sdp-jeita-temp-table = <1000 1030 0 4500000>,
				<1100 1080 1500000 4500000>,
				<1150 1180 1500000 4500000>,
				<1450 1420 5400000 4500000>,
				<1550 1520 3900000 4200000>;
	cdp-jeita-temp-table = <1000 1030 0 4500000>,
				<1100 1080 1500000 4500000>,
				<1150 1180 1500000 4500000>,
				<1450 1420 5400000 4500000>,
				<1550 1520 3900000 4200000>;
	unknown-jeita-temp-table = <1000 1030 0 4500000>,
				<1100 1080 1500000 4500000>,
				<1150 1180 1500000 4500000>,
				<1450 1420 5400000 4500000>,
				<1550 1520 3900000 4200000>;

	fchg-jeita-temp-table = <1000 1030 0 4500000>,
				<1100 1080 1500000 4500000>,
				<1150 1180 1500000 4500000>,
				<1450 1420 5400000 4500000>,
				<1550 1520 3900000 4200000>;
	flash-jeita-temp-table = <1000 1030 0 4500000>,
				<1100 1080 1500000 4500000>,
				<1150 1180 1500000 4500000>,
				<1450 1420 5400000 4500000>,
				<1550 1520 3900000 4200000>;
};

&bat2_1 {
	charge-term-current-microamp = <420000>;
	constant-charge-voltage-max-microvolt = <4468000>;
	constant-charge-current-max-microamp = <8000000>;
	factory-internal-resistance-micro-ohms = <105000>;
	voltage-min-design-microvolt = <3450000>;
	fast-charge-threshold-microvolt = <4100000>;
	fullbatt-voltage = <4368000>;
	fullbatt-current = <120000>;
	fullbatt-track-end-vol = <4300000>;
	fullbatt-track-end-cur = <130000>;
	first-calib-voltage = <3664000>;
	first-calib-capacity = <40>;

	ir-cv-offset-microvolt = <100000>;
	ir-rc-micro-ohms = <20000>;
	ir-us-upper-limit-microvolt = <4500000>;

	ocv-capacity-celsius = <25>;
	batt-id-list = <270 121 430>;  /*kohm, weike, haopeng，utility*/
	charge-full-design-microamp-hours = <8000000>;
	/*7592*0.98 = 7440 */
	charge-full-microamp-hours = <7440000>;

	ocv-capacity-table-0 = <4422000 100>, <4368000 95>, <4318000 90>,
				<4263000 85>, <4204000 80>, <4145000 75>,
				<4089000 70>, <4036000 65>, <3986000 60>,
				<3929000 55>, <3882000 50>, <3850000 45>,
				<3825000 40>, <3804000 35>, <3784000 30>,
				<3753000 25>, <3729000 20>, <3703000 15>,
				<3673000 10>, <3662000 5>, <3400000 0>;
	/* NTC 100k, Vref 1850mV, R pull-up 110K, R pull-down 1000k */
	voltage-temp-table = <1591473 750>, <1555286 800>, <1512176 850>,
				<1459276 900>, <1395886 950>, <1322179 1000>,
				<1238711 1050>, <1147116 1100>, <1049658 1150>,
				<949081 1200>, <848416 1250>, <750447 1300>,
				<657569 1350>, <571537 1400>, <493518 1450>,
				<423845 1500>, <362641 1550>, <309430 1600>,
				<263582 1650>, <221438 1700>, <188468 1750>;
	capacity-temp-table = <25 100>, <10 100>, <0 93>, <(-10) 87>, <(-20) 76>;
	resistance-temp-table = <25 100>, <10 176>, <0 1074>, <(-10) 1171>, <(-20) 1287>;

	charge-sdp-current-microamp = <700000 500000>;
	charge-dcp-current-microamp = <7800000 2000000>;
	charge-cdp-current-microamp = <7800000 1500000>;
	charge-unknown-current-microamp = <1000000 1000000>;
	charge-fchg-current-microamp = <7800000 4000000>;
	charge-flash-current-microamp = <7800000 4000000>;

	dcp-jeita-temp-table = <1000 1030 0 4500000>,
				<1100 1080 1500000 4500000>,
				<1150 1180 1500000 4500000>,
				<1450 1420 5400000 4500000>,
				<1550 1520 3900000 4200000>;
	sdp-jeita-temp-table = <1000 1030 0 4500000>,
				<1100 1080 1500000 4500000>,
				<1150 1180 1500000 4500000>,
				<1450 1420 5400000 4500000>,
				<1550 1520 3900000 4200000>;
	cdp-jeita-temp-table = <1000 1030 0 4500000>,
				<1100 1080 1500000 4500000>,
				<1150 1180 1500000 4500000>,
				<1450 1420 5400000 4500000>,
				<1550 1520 3900000 4200000>;
	unknown-jeita-temp-table = <1000 1030 0 4500000>,
				<1100 1080 1500000 4500000>,
				<1150 1180 1500000 4500000>,
				<1450 1420 5400000 4500000>,
				<1550 1520 3900000 4200000>;

	fchg-jeita-temp-table = <1000 1030 0 4500000>,
				<1100 1080 1500000 4500000>,
				<1150 1180 1500000 4500000>,
				<1450 1420 5400000 4500000>,
				<1550 1520 3900000 4200000>;
	flash-jeita-temp-table = <1000 1030 0 4500000>,
				<1100 1080 1500000 4500000>,
				<1150 1180 1500000 4500000>,
				<1450 1420 5400000 4500000>,
				<1550 1520 3900000 4200000>;
};

&bat2_2 {
	charge-term-current-microamp = <420000>;
	constant-charge-voltage-max-microvolt = <4436000>;
	constant-charge-current-max-microamp = <8000000>;
	factory-internal-resistance-micro-ohms = <105000>;
	voltage-min-design-microvolt = <3450000>;
	fast-charge-threshold-microvolt = <4100000>;
	fullbatt-voltage = <4336000>;
	fullbatt-current = <120000>;
	fullbatt-track-end-vol = <4300000>;
	fullbatt-track-end-cur = <130000>;
	first-calib-voltage = <3664000>;
	first-calib-capacity = <40>;

	ir-cv-offset-microvolt = <100000>;
	ir-rc-micro-ohms = <20000>;
	ir-us-upper-limit-microvolt = <4500000>;

	ocv-capacity-celsius = <25>;
	batt-id-list = <270 121 430>;  /*kohm, weike, haopeng，utility*/
	charge-full-design-microamp-hours = <8000000>;
	/*7354*0.98 = 7260 */
	charge-full-microamp-hours = <7260000>;

	ocv-capacity-table-0 = <4390000 100>, <4338000 95>, <4289000 90>,
				<4236000 85>, <4179000 80>, <4122000 75>,
				<4067000 70>, <4016000 65>, <3968000 60>,
				<3912000 55>, <3867000 50>, <3836000 45>,
				<3812000 40>, <3791000 35>, <3772000 30>,
				<3742000 25>, <3719000 20>, <3693000 15>,
				<3664000 10>, <3654000 5>, <3400000 0>;
	/* NTC 100k, Vref 1850mV, R pull-up 110K, R pull-down 1000k */
	voltage-temp-table = <1591473 750>, <1555286 800>, <1512176 850>,
				<1459276 900>, <1395886 950>, <1322179 1000>,
				<1238711 1050>, <1147116 1100>, <1049658 1150>,
				<949081 1200>, <848416 1250>, <750447 1300>,
				<657569 1350>, <571537 1400>, <493518 1450>,
				<423845 1500>, <362641 1550>, <309430 1600>,
				<263582 1650>, <221438 1700>, <188468 1750>;
	capacity-temp-table = <25 100>, <10 100>, <0 93>, <(-10) 87>, <(-20) 76>;
	resistance-temp-table = <25 100>, <10 176>, <0 1074>, <(-10) 1171>, <(-20) 1287>;

	charge-sdp-current-microamp = <700000 500000>;
	charge-dcp-current-microamp = <7800000 2000000>;
	charge-cdp-current-microamp = <7800000 1500000>;
	charge-unknown-current-microamp = <1000000 1000000>;
	charge-fchg-current-microamp = <7800000 4000000>;
	charge-flash-current-microamp = <7800000 4000000>;

	dcp-jeita-temp-table = <1000 1030 0 4500000>,
				<1100 1080 1500000 4500000>,
				<1150 1180 1500000 4500000>,
				<1450 1420 5400000 4500000>,
				<1550 1520 3900000 4200000>;
	sdp-jeita-temp-table = <1000 1030 0 4500000>,
				<1100 1080 1500000 4500000>,
				<1150 1180 1500000 4500000>,
				<1450 1420 5400000 4500000>,
				<1550 1520 3900000 4200000>;
	cdp-jeita-temp-table = <1000 1030 0 4500000>,
				<1100 1080 1500000 4500000>,
				<1150 1180 1500000 4500000>,
				<1450 1420 5400000 4500000>,
				<1550 1520 3900000 4200000>;
	unknown-jeita-temp-table = <1000 1030 0 4500000>,
				<1100 1080 1500000 4500000>,
				<1150 1180 1500000 4500000>,
				<1450 1420 5400000 4500000>,
				<1550 1520 3900000 4200000>;

	fchg-jeita-temp-table = <1000 1030 0 4500000>,
				<1100 1080 1500000 4500000>,
				<1150 1180 1500000 4500000>,
				<1450 1420 5400000 4500000>,
				<1550 1520 3900000 4200000>;
	flash-jeita-temp-table = <1000 1030 0 4500000>,
				<1100 1080 1500000 4500000>,
				<1150 1180 1500000 4500000>,
				<1450 1420 5400000 4500000>,
				<1550 1520 3900000 4200000>;
};

&bat2_3 {
	charge-term-current-microamp = <420000>;
	constant-charge-voltage-max-microvolt = <4336000>;
	constant-charge-current-max-microamp = <8000000>;
	factory-internal-resistance-micro-ohms = <105000>;
	voltage-min-design-microvolt = <3450000>;
	fast-charge-threshold-microvolt = <4100000>;
	fullbatt-voltage = <4236000>;
	fullbatt-current = <120000>;
	fullbatt-track-end-vol = <4300000>;
	fullbatt-track-end-cur = <130000>;
	first-calib-voltage = <3664000>;
	first-calib-capacity = <40>;

	ir-cv-offset-microvolt = <100000>;
	ir-rc-micro-ohms = <20000>;
	ir-us-upper-limit-microvolt = <4500000>;

	ocv-capacity-celsius = <25>;
	batt-id-list = <270 121 430>;  /*kohm, weike, haopeng，utility*/
	charge-full-design-microamp-hours = <8000000>;
	/*6611*0.98 = 7644 */
	charge-full-microamp-hours = <6478000>;

	ocv-capacity-table-0 = <4290000 100>, <4243000 95>, <4199000 90>,
				<4152000 85>, <4100000 80>, <4049000 75>,
				<4000000 70>, <3953000 65>, <3910000 60>,
				<3861000 55>, <3820000 50>, <3792000 45>,
				<3770000 40>, <3752000 35>, <3735000 30>,
				<3708000 25>, <3687000 20>, <3664000 15>,
				<3638000 10>, <3628000 5>, <3400000 0>;
	/* NTC 100k, Vref 1850mV, R pull-up 110K, R pull-down 1000k */
	voltage-temp-table = <1591473 750>, <1555286 800>, <1512176 850>,
				<1459276 900>, <1395886 950>, <1322179 1000>,
				<1238711 1050>, <1147116 1100>, <1049658 1150>,
				<949081 1200>, <848416 1250>, <750447 1300>,
				<657569 1350>, <571537 1400>, <493518 1450>,
				<423845 1500>, <362641 1550>, <309430 1600>,
				<263582 1650>, <221438 1700>, <188468 1750>;
	capacity-temp-table = <25 100>, <10 100>, <0 93>, <(-10) 87>, <(-20) 76>;
	resistance-temp-table = <25 100>, <10 176>, <0 1074>, <(-10) 1171>, <(-20) 1287>;

	charge-sdp-current-microamp = <700000 500000>;
	charge-dcp-current-microamp = <7800000 2000000>;
	charge-cdp-current-microamp = <7800000 1500000>;
	charge-unknown-current-microamp = <1000000 1000000>;
	charge-fchg-current-microamp = <7800000 4000000>;
	charge-flash-current-microamp = <7800000 4000000>;

	dcp-jeita-temp-table = <1000 1030 0 4500000>,
				<1100 1080 1500000 4500000>,
				<1150 1180 1500000 4500000>,
				<1450 1420 5400000 4500000>,
				<1550 1520 3900000 4200000>;
	sdp-jeita-temp-table = <1000 1030 0 4500000>,
				<1100 1080 1500000 4500000>,
				<1150 1180 1500000 4500000>,
				<1450 1420 5400000 4500000>,
				<1550 1520 3900000 4200000>;
	cdp-jeita-temp-table = <1000 1030 0 4500000>,
				<1100 1080 1500000 4500000>,
				<1150 1180 1500000 4500000>,
				<1450 1420 5400000 4500000>,
				<1550 1520 3900000 4200000>;
	unknown-jeita-temp-table = <1000 1030 0 4500000>,
				<1100 1080 1500000 4500000>,
				<1150 1180 1500000 4500000>,
				<1450 1420 5400000 4500000>,
				<1550 1520 3900000 4200000>;

	fchg-jeita-temp-table = <1000 1030 0 4500000>,
				<1100 1080 1500000 4500000>,
				<1150 1180 1500000 4500000>,
				<1450 1420 5400000 4500000>,
				<1550 1520 3900000 4200000>;
	flash-jeita-temp-table = <1000 1030 0 4500000>,
				<1100 1080 1500000 4500000>,
				<1150 1180 1500000 4500000>,
				<1450 1420 5400000 4500000>,
				<1550 1520 3900000 4200000>;
};

&cm {
	compatible = "charger-manager";
	status = "okay";
	cm-name = "battery";
	cm-poll-mode = <2>;
	cm-poll-interval = <15000>;
	cm-battery-stat = <2>;

	cm-fullbatt-vchkdrop-ms = <30000>;
	cm-fullbatt-vchkdrop-volt = <60000>;
	cm-fullbatt-capacity = <100>;
	/*Charge pump target charge current*/
	cm-cp-taper-current = <1000000>;

	cm-chargers = "charger_psy";
	zte-cm-charger = "zte_charger_psy";
	zte-cm-fuel-gauge = "zte-fgu";

	cm-fuel-gauge = "sc27xx-fgu";

	/* in deci centigrade */
	cm-battery-cold = <200>;
	cm-battery-cold-in-minus;
	cm-battery-hot = <800>;
	cm-battery-temp-diff = <100>;

	/* Allow charging for 6hr */
	cm-charging-max = <21600000>;
	/* recovery charging after stop charging 45min */
	cm-discharging-max = <2700000>;

	/* the interval to feed charger watchdog */
	cm-wdt-interval = <60>;

	/* drop voltage in microVolts to allow shutdown */
	cm-shutdown-voltage = <3100000>;

	/* when 99% of the time is exceeded, it will be forced to 100% */
	cm-tickle-time-out = <1500>;

	/* how much time to allow capacity change */
	cm-one-cap-time = <30>;

	/* because kernel not load thermal-gerneric-adc.ko in charger mode, then battery uevent can't broadcast to ztecharger */
	/* cm-thermal-zone = "board-thmzone"; */

	/* when the safe charging voltage is exceeded, stop charging */
	cm-charge-voltage-max = <6500000>;
	cm-fast-charge-voltage-max = <10500000>;
	cm-flash-charge-voltage-max = <12000000>;
	/* drop voltage in microVolts to restart charging */
	cm-charge-voltage-drop = <700000>;
	cm-fast-charge-voltage-drop = <700000>;
	cm-flash-charge-voltage-drop = <1000000>;

	/* sprd_fchg parameter */
	sprd,support-fchg;
	sprd,support-pd-pps;
	sprd,pd-fixed-max-microwatt = <30000000>;

	monitored-battery-0 = <&bat0_0 &bat0_1 &bat0_2 &bat0_3>;
	monitored-battery-1 = <&bat1_0 &bat1_1 &bat1_2 &bat1_3>;
	monitored-battery-2 = <&bat2_0 &bat2_1 &bat2_2 &bat2_3>;
	cm-capacity-track;
	cm-keep-awake;

	phys = <&ssphy>;
	pd-extcon-enable;
	extcon = <&pmic_typec>, <&pmic_pd>;
	use-typec-extcon;
};

/ {
	zte_misc: zte_misc {
		status = "okay";
		compatible = "zte-misc";
	};
};

&i2c6 {
	#address-cells = <1>;
	#size-cells = <0>;

	status = "okay";

	bq2560x_chg: charger@6b {
		compatible = "ti,bq2560x_chg", "ti,bq25890_chg";
		reg = <0x6b>;
		phys = <&hsphy>;
		monitored-battery-0 = <&bat0_0 &bat0_1 &bat0_2 &bat0_3>;
		monitored-battery-1 = <&bat1_0 &bat1_1 &bat1_2 &bat1_3>;
		monitored-battery-2 = <&bat2_0 &bat2_1 &bat2_2 &bat2_3>;
		extcon = <&pmic_typec>;
		vindpm-value = <4270>;
		use-typec-extcon;
		vddvbus:otg-vbus {
			regulator-name = "vddvbus";
		};
	};
};

&i2c2 {
	status = "okay";
	nu2115-standalone@6d {
		compatible = "nu2115-standalone";
		status = "okay";
		reg = <0x6d>;
		gpio_int = <&ap_gpio 186 0x0>;
		extcon = <&pmic_typec>;
	};

	sc8541@6a{
        compatible = "sc,sc8541-standalone";
        reg = <0x6a>;
        sc8541,intr_gpio = <&ap_gpio 186 0x0>;
        extcon = <&pmic_typec>;

        charger_name = "primary_dvchg";
        sc,sc8541,vbat-ovp-dis = <0>;
        sc,sc8541,vbat-ovp = <90>; /*3840 + val * 10*/
        sc,sc8541,vbat-ovp-alm-dis = <1>;
        sc,sc8541,vbat-ovp-alm = <70>; /*3840 + val * 10*/
        sc,sc8541,ibat-ocp-dis = <0>;
        sc,sc8541,ibat-ocp  = <81>; /*val * 100*/
        sc,sc8541,ibat-ocp-alm-dis = <1>;
        sc,sc8541,ibat-ocp-alm = <80>; /*val * 100*/
        sc,sc8541,ibus-ucp-dis = <0>;
        sc,sc8541,vbus-in-range-dis = <0>;
        sc,sc8541,vbus-pd-en = <0>;
        sc,sc8541,vbus-ovp = <38>; /*7000 + val * 50*/
        sc,sc8541,vbus-ovp-alm-dis = <1>;
        sc,sc8541,vbus-ovp-alm = <34>; /*7000 + val * 50*/
        sc,sc8541,ibus-ocp-dis = <0>;
        sc,sc8541,ibus-ocp = <13>; /*1000 + val * 250*/
        sc,sc8541,tshut-dis = <1>;
        sc,sc8541,tsbus-flt-dis = <1>;
        sc,sc8541,tsbat-flt-dis = <1>;
        sc,sc8541,tdie-alm = <200>; /*25 + val * 0.5*/
        sc,sc8541,tsbus-flt = <21>;
        sc,sc8541,tsbat-flt = <21>;
        sc,sc8541,vac1-ovp = <2>; /*0:6.5V 1:10.5V 2:12V 3:14V 4:16V 5~7:18V*/
        sc,sc8541,vac2-ovp = <2>; /*0:6.5V 1:10.5V 2:12V 3:14V 4:16V 5~7:18V*/
        sc,sc8541,vac1-pd-en = <0>;
        sc,sc8541,vac2-pd-en = <0>;
        sc,sc8541,fsw-set = <4>; /*0:200KHz 1:300KHz 2:400KHz 
                    3:500KHz 4:600KHz 5:650KHz 6:700KHz 7:750KHz*/
        sc,sc8541,wd-timeout = <0>; /*0:0.5s 1:1s 2:5s 3:30s*/
        sc,sc8541,wd-timeout-dis = <1>;
        sc,sc8541,ibat-sns-r = <0>; /*0:2mho 1:5mho*/
        sc,sc8541,ss-timeout = <7>; /*0:6.25ms 1:12.5ms 2:25ms 3:50ms 
                    4:100ms 5:400ms 6:1.5s 7:10s*/
        sc,sc8541,ibus-ucp-fall-dg = <1>;
        sc,sc8541,vout-ovp-dis = <0>;
        sc,sc8541,vout-ovp = <3>; /*4700 + val * 100*/
        sc,sc8541,ms = <0>; /*standalone*/
        sc,sc8541,pmid2out-uvp = <7>; /*50 + val * 25*/
        sc,sc8541,pmid2out-ovp = <7>; /*150 + val * 50*/
    };
};

&pmic_fgu {
	monitored-battery-0 = <&bat0_0 &bat0_1 &bat0_2 &bat0_3>;
	monitored-battery-1 = <&bat1_0 &bat1_1 &bat1_2 &bat1_3>;
	monitored-battery-2 = <&bat2_0 &bat2_1 &bat2_2 &bat2_3>;
	fgu-cap-remap-table = <98 99 2>, <99 100 3>;
	sprd,calib-resistance-micro-ohms = <3000>;
	sprd,comp-resistance-mohm = <11>;
	io-channels = <&pmic_adc 6>, <&pmic_adc 0>, <&pmic_adc 14>;
	io-channel-names = "adc-batt-id", "bat-temp", "charge-vol";
	fgu-capacity-track;
	phys = <&ssphy>;

	sprd,bat-aging;
	bat-0-aging-cycles = <0>, <100>, <300>, <1000>;
	bat-0-aging-fcc-uah = <7644000>, <7302000>, <7059000>, <6352000>;
	bat-1-aging-cycles = <0>, <100>, <300>, <1000>;
	bat-1-aging-fcc-uah = <7644000>, <7301000>, <7058000>, <6350000>;
	bat-2-aging-cycles = <0>, <100>, <300>, <1000>;
	bat-2-aging-fcc-uah = <7644000>, <7301000>, <7058000>, <6350000>;

	sprd,relax-counter-threshold = <580>;
	sprd,relax-current-threshold = <30>;
	sprd,capacity-sleep-calibration;

	sprd,capacity-boot-calibration;
	extcon = <&pmic_typec>;
	sprd,zte-low-temp-algo;
	use-typec-extcon;
	extcon = <&pmic_typec>;
};

&pmic_fchg {
	status = "okay";
	phys = <&ssphy>;
	sprd,input-voltage-microvolt = <5000000>;
};

&pmic_pd {
	status = "okay";
	vbus-supply = <&vddvbus>;
	use-pdhub-c2c;
	sprd,syscon-aon-apb = <&aon_apb_regs>;
	vconn-supply = <&vddldo2>;
	usb_con: connector {
		compatible = "usb-c-connector";
		label = "USB-C";
		power-role = "dual";
		try-power-role = "sink";
		source-pdos = <PDO_FIXED(5000, 1000, PDO_FIXED_USB_COMM |
				PDO_FIXED_DUAL_ROLE | PDO_FIXED_DATA_SWAP)>;
		sink-pdos = <PDO_FIXED(5000, 3000, PDO_FIXED_USB_COMM)
				PDO_PPS_APDO(3300, 11000, 6000)>;
		op-sink-microwatt = <10000000>;
	};
};

#include "../bat_setting/battery_protect_policy_080509200178_48.dtsi"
